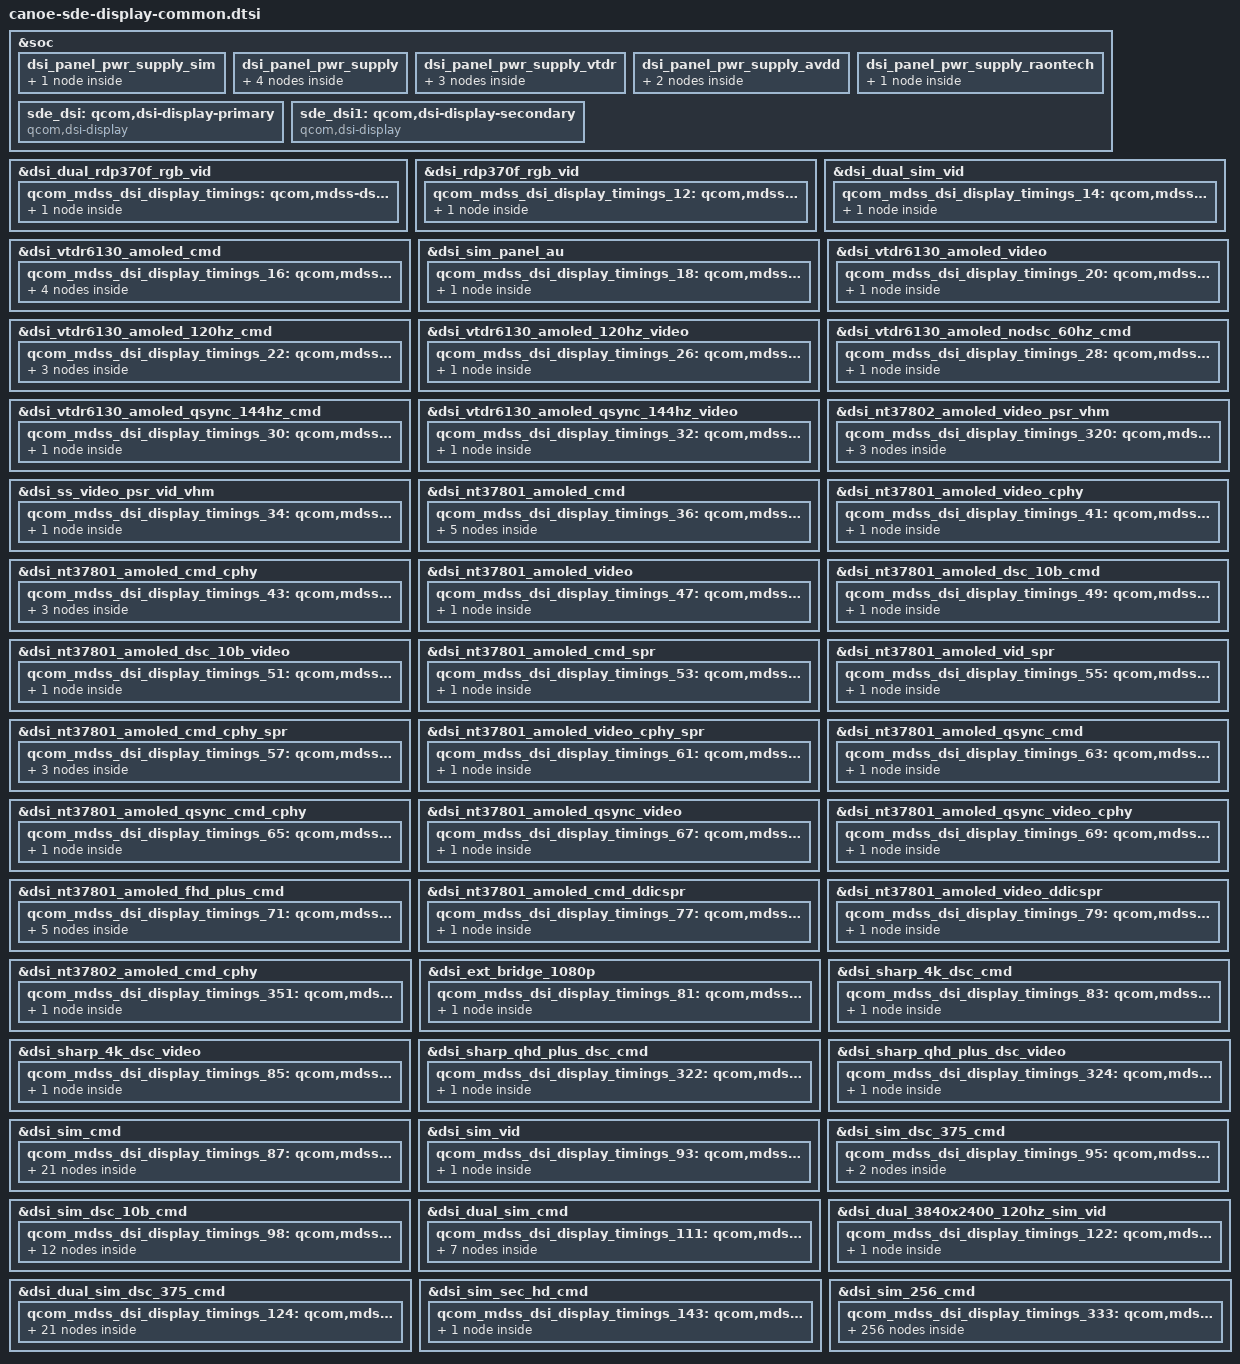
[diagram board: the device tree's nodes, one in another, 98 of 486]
// SPDX-License-Identifier: BSD-3-Clause
/*
 * Copyright (c) Qualcomm Technologies, Inc. and/or its subsidiaries.
 */

#include "dsi-panel-nt37801-dsc-wqhd-plus-cmd.dtsi"
#include "dsi-panel-nt37801-dsc-wqhd-plus-cmd-cphy.dtsi"
#include "dsi-panel-nt37801-dsc-wqhd-plus-video.dtsi"
#include "dsi-panel-nt37801-dsc-wqhd-plus-video-cphy.dtsi"
#include "dsi-panel-nt37801-dsc-10bit-cmd.dtsi"
#include "dsi-panel-nt37801-dsc-10bit-video.dtsi"
#include "dsi-panel-nt37801-dsc-wqhd-plus-cmd-spr.dtsi"
#include "dsi-panel-nt37801-dsc-wqhd-plus-video-spr.dtsi"
#include "dsi-panel-nt37801-qsync-dsc-wqhd-plus-cmd.dtsi"
#include "dsi-panel-nt37801-qsync-dsc-wqhd-plus-cmd-cphy.dtsi"
#include "dsi-panel-nt37801-qsync-dsc-wqhd-plus-video.dtsi"
#include "dsi-panel-nt37801-qsync-dsc-wqhd-plus-video-cphy.dtsi"
#include "dsi-panel-nt37801-dsc-fhd-plus-cmd.dtsi"
#include "dsi-panel-nt37801-dsc-wqhd-plus-cmd-ddicspr.dtsi"
#include "dsi-panel-nt37801-dsc-wqhd-plus-video-ddicspr.dtsi"
#include "dsi-panel-nt37801-dsc-wqhd-plus-cmd-cphy-spr.dtsi"
#include "dsi-panel-nt37801-dsc-wqhd-plus-video-cphy-spr.dtsi"
#include "dsi-panel-nt37802-amoled-video-psr-vhm.dtsi"
#include "dsi-panel-nt37802-dsc-wqhd-plus-cmd-cphy.dtsi"
#include "dsi-panel-sharp-dsc-4k-cmd.dtsi"
#include "dsi-panel-sharp-dsc-4k-video.dtsi"
#include "dsi-panel-sharp-dsc-qhd-plus-cmd.dtsi"
#include "dsi-panel-sharp-dsc-qhd-plus-video.dtsi"
#include "dsi-panel-sim-cmd-au.dtsi"
#include "dsi-panel-sim-cmd.dtsi"
#include "dsi-panel-sim-256-cmd.dtsi"
#include "dsi-panel-sim-dsc-10bit-cmd.dtsi"
#include "dsi-panel-sim-dsc375-cmd.dtsi"
#include "dsi-panel-sim-dualmipi-cmd.dtsi"
#include "dsi-panel-sim-dualmipi-dsc375-cmd.dtsi"
#include "dsi-panel-sim-dualmipi-video.dtsi"
#include "dsi-panel-sim-dualmipi-3840x2400-120hz-video.dtsi"
#include "dsi-panel-sim-sec-hd-cmd.dtsi"
#include "dsi-panel-sim-video.dtsi"
#include "dsi-panel-ss-video-psr-vid-vhm.dtsi"
#include "dsi-panel-vtdr6130-dsc-fhd-plus-120hz-cmd.dtsi"
#include "dsi-panel-vtdr6130-dsc-fhd-plus-120hz-video.dtsi"
#include "dsi-panel-vtdr6130-nodsc-fhd-plus-60hz-cmd.dtsi"
#include "dsi-panel-vtdr6130-dsc-fhd-plus-cmd.dtsi"
#include "dsi-panel-vtdr6130-dsc-fhd-plus-video.dtsi"
#include "dsi-panel-vtdr6130-qsync-dsc-fhd-plus-144hz-cmd.dtsi"
#include "dsi-panel-vtdr6130-qsync-dsc-fhd-plus-144hz-video.dtsi"
#include "dsi-panel-dual-rdp370f-rgb-video.dtsi"
#include "dsi-panel-rdp370f-rgb-video.dtsi"
#include "dsi-panel-ext-bridge-1080p.dtsi"

#include "canoe-sde-display-pinctrl-common.dtsi"

&soc {
	dsi_panel_pwr_supply_sim: dsi_panel_pwr_supply_sim {
		#address-cells = <1>;
		#size-cells = <0>;

		qcom_panel_supply_entry_0: qcom,panel-supply-entry@0 {
			reg = <0>;
			qcom,supply-name = "dummy";
			qcom,supply-min-voltage = <1800000>;
			qcom,supply-max-voltage = <1800000>;
			qcom,supply-enable-load = <220000>;
			qcom,supply-disable-load = <8000>;
			qcom,supply-post-on-sleep = <20>;
		};
	};

	dsi_panel_pwr_supply: dsi_panel_pwr_supply {
		#address-cells = <1>;
		#size-cells = <0>;

		qcom_panel_supply_entry_0_5: qcom,panel-supply-entry@0 {
			reg = <0>;
			qcom,supply-name = "vddio";
			qcom,supply-min-voltage = <1800000>;
			qcom,supply-max-voltage = <1800000>;
			qcom,supply-enable-load = <154000>;
			qcom,supply-disable-load = <277>;
			qcom,supply-post-on-sleep = <20>;
		};

		qcom_panel_supply_entry_1: qcom,panel-supply-entry@1 {
			reg = <1>;
			qcom,supply-name = "vdd";
			qcom,supply-min-voltage = <1045000>;
			qcom,supply-max-voltage = <1100000>;
			qcom,supply-enable-load = <220000>;
			qcom,supply-disable-load = <3>;
			qcom,supply-post-on-sleep = <0>;
		};

		qcom_panel_supply_entry_2: qcom,panel-supply-entry@2 {
			reg = <2>;
			qcom,supply-name = "vci";
			qcom,supply-min-voltage = <3000000>;
			qcom,supply-max-voltage = <3000000>;
			qcom,supply-enable-load = <10000>;
			qcom,supply-disable-load = <1>;
			qcom,supply-post-on-sleep = <0>;
		};

		qcom_panel_supply_entry_3: qcom,panel-supply-entry@3 {
			reg = <3>;
			qcom,supply-name = "tvdd";
			qcom,supply-min-voltage = <1800000>;
			qcom,supply-max-voltage = <1800000>;
			qcom,supply-enable-load = <0>;
			qcom,supply-disable-load = <0>;
			qcom,supply-post-on-sleep = <20>;
		};
	};

	dsi_panel_pwr_supply_vtdr: dsi_panel_pwr_supply_vtdr {
		#address-cells = <1>;
		#size-cells = <0>;

		qcom_panel_supply_entry_0_6: qcom,panel-supply-entry@0 {
			reg = <0>;
			qcom,supply-name = "vddio";
			qcom,supply-min-voltage = <1800000>;
			qcom,supply-max-voltage = <1800000>;
			qcom,supply-enable-load = <220000>;
			qcom,supply-disable-load = <8000>;
			qcom,supply-post-on-sleep = <20>;
		};

		qcom_panel_supply_entry_1_7: qcom,panel-supply-entry@1 {
			reg = <1>;
			qcom,supply-name = "vci";
			qcom,supply-min-voltage = <3000000>;
			qcom,supply-max-voltage = <3000000>;
			qcom,supply-enable-load = <10000>;
			qcom,supply-disable-load = <300>;
			qcom,supply-post-on-sleep = <1>;
			qcom,supply-post-off-sleep = <2>;
		};

		qcom_panel_supply_entry_2_8: qcom,panel-supply-entry@2 {
			reg = <2>;
			qcom,supply-name = "vdd";
			qcom,supply-min-voltage = <1200000>;
			qcom,supply-max-voltage = <1292000>;
			qcom,supply-enable-load = <200000>;
			qcom,supply-disable-load = <0>;
			qcom,supply-post-on-sleep = <0>;
			qcom,supply-post-off-sleep = <2>;
		};
	};

	dsi_panel_pwr_supply_avdd: dsi_panel_pwr_supply_avdd {
		#address-cells = <1>;
		#size-cells = <0>;

		qcom_panel_supply_entry_0_9: qcom,panel-supply-entry@0 {
			reg = <0>;
			qcom,supply-name = "vddio";
			qcom,supply-min-voltage = <1800000>;
			qcom,supply-max-voltage = <1800000>;
			qcom,supply-enable-load = <220000>;
			qcom,supply-disable-load = <8000>;
			qcom,supply-post-on-sleep = <20>;
		};

		qcom_panel_supply_entry_1_10: qcom,panel-supply-entry@1 {
			reg = <1>;
			qcom,supply-name = "avdd";
			qcom,supply-min-voltage = <4600000>;
			qcom,supply-max-voltage = <7500000>;
			qcom,supply-enable-load = <33000>;
			qcom,supply-disable-load = <1>;
		};
	};

	dsi_panel_pwr_supply_raontech: dsi_panel_pwr_supply_raontech {
		#address-cells = <1>;
		#size-cells = <0>;

		qcom_panel_supply_entry_0_11: qcom,panel-supply-entry@0 {
			reg = <0>;
			qcom,supply-name = "avdd";
			qcom,supply-min-voltage = <4600000>;
			qcom,supply-max-voltage = <7500000>;
			qcom,supply-enable-load = <33000>;
			qcom,supply-disable-load = <1>;
		};
	};

	sde_dsi: qcom,dsi-display-primary {
		compatible = "qcom,dsi-display";
		label = "primary";
		qcom,op-label = "hwio";
		status = "ok";

		qcom,dsi-ctrl = <&mdss_dsi0 &mdss_dsi1>;
		qcom,dsi-phy = <&mdss_dsi_phy0 &mdss_dsi_phy1>;

		qcom,platform-te-gpio = <&tlmm 86 0>;
		qcom,panel-te-source = <0>;

		qcom,mdp = <&mdss_mdp>;
		qcom,dsi-default-panel = <&dsi_nt37801_amoled_cmd>;
		qcom,demura-panel-id = <0x0122e700 0x00000471>;
	};

	sde_dsi1: qcom,dsi-display-secondary {
		compatible = "qcom,dsi-display";
		label = "secondary";
		qcom,op-label = "hwio";
		status = "ok";

		qcom,dsi-ctrl = <&mdss_dsi0 &mdss_dsi1>;
		qcom,dsi-phy = <&mdss_dsi_phy0 &mdss_dsi_phy1>;

		qcom,platform-te-gpio = <&tlmm 87 0>;
		qcom,panel-te-source = <1>;

		qcom,mdp = <&mdss_mdp>;
		qcom,demura-panel-id = <0x0 0x0>;
	};
};

&dsi_dual_rdp370f_rgb_vid {
	qcom,dsi-select-clocks = "pll_byte_clk0", "pll_dsi_clk0";

	qcom,mdss-dsi-panel-status-check-mode = "esd_sw_sim_success";
	qcom,esd-check-enabled;

	qcom_mdss_dsi_display_timings: qcom,mdss-dsi-display-timings {
		timing_0: timing@0 {
			qcom,mdss-dsi-panel-phy-timings = [00 2d 0c 0c 1d 1c 0c
				0c 0b 02 04 00 25 11];
			qcom,display-topology = <2 0 2>;
			qcom,default-topology-index = <0>;
		};
	};
};

&dsi_rdp370f_rgb_vid {
	qcom,dsi-select-clocks = "pll_byte_clk0", "pll_dsi_clk0";

	qcom,mdss-dsi-panel-status-check-mode = "esd_sw_sim_success";
	qcom,esd-check-enabled;

	qcom_mdss_dsi_display_timings_12: qcom,mdss-dsi-display-timings {
		timing_0_13: timing@0 {
			qcom,mdss-dsi-panel-phy-timings = [00 2d 0c 0c 1d 1c 0c
				0c 0b 02 04 00 25 11];
			qcom,display-topology = <1 0 1>;
			qcom,default-topology-index = <0>;
		};
	};
};

&dsi_dual_sim_vid {
	qcom,dsi-select-clocks = "pll_byte_clk0", "pll_dsi_clk0";

	qcom_mdss_dsi_display_timings_14: qcom,mdss-dsi-display-timings {
		timing_0_15: timing@0 {
			qcom,mdss-dsi-panel-phy-timings = [00 1a 07 06 16 21 07
				07 07 02 04 00 17 0c];
			qcom,display-topology = <2 0 2>;
			qcom,default-topology-index = <0>;
		};
	};
};

/* PHY TIMINGS REVISION YL with reduced margins */
&dsi_vtdr6130_amoled_cmd {
	qcom,dsi-select-clocks = "pll_byte_clk0", "pll_dsi_clk0";
	qcom,dsi-select-sec-clocks = "pll_byte_clk1", "pll_dsi_clk1";

	qcom,dsi-dyn-clk-enable;

	qcom,esd-check-enabled;
	qcom,mdss-dsi-panel-status-check-mode = "reg_read";
	qcom,mdss-dsi-panel-status-command = [06 01 00 01 00 00 01 0a];
	qcom,mdss-dsi-panel-status-command-state = "dsi_lp_mode";
	qcom,mdss-dsi-panel-status-value = <0x9c>;
	qcom,mdss-dsi-panel-status-read-length = <1>;

	qcom,mdss-dsi-panel-hdr-enabled;

	qcom_mdss_dsi_display_timings_16: qcom,mdss-dsi-display-timings {
		timing_0_17: timing@0 {
			qcom,mdss-dsi-panel-phy-timings = [00 1c 08 07 17 22 07
				07 08 02 04 00 19 0c];
			qcom,display-topology = <2 2 1>;
			qcom,default-topology-index = <0>;
			qcom,dsi-dyn-clk-list = <813936000 818175250 822414500>;
		};

		timing_1: timing@1 {
			qcom,mdss-dsi-panel-phy-timings = [00 1c 08 07 17 22 07
				07 08 02 04 00 19 0c];
			qcom,display-topology = <2 2 1>;
			qcom,default-topology-index = <0>;
			qcom,dsi-dyn-clk-list = <813936000 818175250 822414500>;
		};

		timing_2: timing@2 {
			qcom,mdss-dsi-panel-phy-timings = [00 1c 08 07 17 22 07
				07 08 02 04 00 19 0c];
			qcom,display-topology = <2 2 1>;
			qcom,default-topology-index = <0>;
			qcom,dsi-dyn-clk-list = <813936000 818175250 822414500>;
		};

		timing_3: timing@3 {
			qcom,mdss-dsi-panel-phy-timings = [00 1c 08 07 17 22 07
				07 08 02 04 00 19 0c];
			qcom,display-topology = <2 2 1>;
			qcom,default-topology-index = <0>;
			qcom,dsi-dyn-clk-list = <813936000 818175250 822414500>;
		};
	};
};

&dsi_sim_panel_au {
	qcom,dsi-select-clocks = "pll_byte_clk0", "pll_dsi_clk0";
	qcom_mdss_dsi_display_timings_18: qcom,mdss-dsi-display-timings {
		timing_0_19: timing@0 {
			qcom,mdss-dsi-panel-phy-timings = [00 1c 08 07 17 22 07
				07 08 02 04 00 19 0c];
			qcom,display-topology = <2 2 1>;
			qcom,default-topology-index = <0>;
		};
	};
};

&dsi_vtdr6130_amoled_video {
	qcom,dsi-select-clocks = "pll_byte_clk0", "pll_dsi_clk0";
	qcom,dsi-select-sec-clocks = "pll_byte_clk1", "pll_dsi_clk1";
	qcom,dsi-supported-dfps-list = <144 120 90 60>;
	qcom,mdss-dsi-pan-enable-dynamic-fps;
	qcom,mdss-dsi-pan-fps-update = "dfps_immediate_porch_mode_vfp";

	qcom,dsi-dyn-clk-enable;
	qcom,dsi-dyn-clk-type = "constant-fps-adjust-hfp";

	qcom,esd-check-enabled;
	qcom,mdss-dsi-panel-status-check-mode = "reg_read";
	qcom,mdss-dsi-panel-status-command = [06 01 00 01 00 00 01 0a];
	qcom,mdss-dsi-panel-status-command-state = "dsi_lp_mode";
	qcom,mdss-dsi-panel-status-value = <0x9c>;
	qcom,mdss-dsi-panel-status-read-length = <1>;

	qcom,mdss-dsi-panel-hdr-enabled;

	qcom_mdss_dsi_display_timings_20: qcom,mdss-dsi-display-timings {
		timing_0_21: timing@0 {
			qcom,mdss-dsi-panel-phy-timings = [00 1c 08 07 17 22 07
				07 08 02 04 00 19 0c];
			qcom,display-topology = <2 2 1>;
			qcom,default-topology-index = <0>;
			qcom,dsi-dyn-clk-list = <847480320 844537680 841595040>;
		};
	};
};

&dsi_vtdr6130_amoled_120hz_cmd {
	qcom,dsi-select-clocks = "pll_byte_clk0", "pll_dsi_clk0";

	qcom,esd-check-enabled;
	qcom,mdss-dsi-panel-status-check-mode = "reg_read";
	qcom,mdss-dsi-panel-status-command = [06 01 00 01 00 00 01 0a];
	qcom,mdss-dsi-panel-status-command-state = "dsi_lp_mode";
	qcom,mdss-dsi-panel-status-value = <0x9c>;
	qcom,mdss-dsi-panel-status-read-length = <1>;

	qcom,mdss-dsi-panel-hdr-enabled;

	qcom_mdss_dsi_display_timings_22: qcom,mdss-dsi-display-timings {
		timing_0_23: timing@0 {
			qcom,mdss-dsi-panel-phy-timings = [00 19 06 06 15 20 07
				06 07 02 04 00 16 0b];
			qcom,display-topology = <2 2 1>;
			qcom,default-topology-index = <0>;
		};

		timing_1_24: timing@1 {
			qcom,mdss-dsi-panel-phy-timings = [00 19 06 06 15 20 07
				06 07 02 04 00 16 0b];
			qcom,display-topology = <2 2 1>;
			qcom,default-topology-index = <0>;
		};

		timing_2_25: timing@2 {
			qcom,mdss-dsi-panel-phy-timings = [00 19 06 06 15 20 07
				06 07 02 04 00 16 0b];
			qcom,display-topology = <2 2 1>;
			qcom,default-topology-index = <0>;
		};
	};
};

&dsi_vtdr6130_amoled_120hz_video {
	qcom,dsi-select-clocks = "pll_byte_clk0", "pll_dsi_clk0";
	qcom,dsi-supported-dfps-list = <120 90 60>;
	qcom,mdss-dsi-pan-enable-dynamic-fps;
	qcom,mdss-dsi-pan-fps-update = "dfps_immediate_porch_mode_vfp";

	qcom,esd-check-enabled;
	qcom,mdss-dsi-panel-status-check-mode = "reg_read";
	qcom,mdss-dsi-panel-status-command = [06 01 00 01 00 00 01 0a];
	qcom,mdss-dsi-panel-status-command-state = "dsi_lp_mode";
	qcom,mdss-dsi-panel-status-value = <0x9c>;
	qcom,mdss-dsi-panel-status-read-length = <1>;

	qcom,mdss-dsi-panel-hdr-enabled;

	qcom_mdss_dsi_display_timings_26: qcom,mdss-dsi-display-timings {
		timing_0_27: timing@0 {
			qcom,mdss-dsi-panel-phy-timings = [00 19 06 06 15 20 07
				06 07 02 04 00 16 0b];
			qcom,display-topology = <2 2 1>;
			qcom,default-topology-index = <0>;
		};
	};
};

&dsi_vtdr6130_amoled_nodsc_60hz_cmd {
	qcom,dsi-select-clocks = "pll_byte_clk0", "pll_dsi_clk0";

	qcom_mdss_dsi_display_timings_28: qcom,mdss-dsi-display-timings {
		timing_0_29: timing@0 {
			qcom,mdss-dsi-panel-phy-timings = [00 21 08 08 19 23 09
				08 09 02 04 00 1c 0d];
			qcom,display-topology = <1 0 1>;
			qcom,default-topology-index = <0>;
		};
	};
};

&dsi_vtdr6130_amoled_qsync_144hz_cmd {
	qcom,dsi-select-clocks = "pll_byte_clk0", "pll_dsi_clk0";
	qcom,esd-check-enabled;
	qcom,mdss-dsi-panel-status-check-mode = "reg_read";
	qcom,mdss-dsi-panel-status-command = [06 01 00 01 00 00 01 0a];
	qcom,mdss-dsi-panel-status-command-state = "dsi_lp_mode";
	qcom,mdss-dsi-panel-status-value = <0x9c>;
	qcom,mdss-dsi-panel-status-read-length = <1>;

	qcom,mdss-dsi-panel-hdr-enabled;

	qcom_mdss_dsi_display_timings_30: qcom,mdss-dsi-display-timings {
		timing_0_31: timing@0 {
			qcom,mdss-dsi-panel-phy-timings = [00 1c 08 07 17 22 07
				07 08 02 04 00 19 0c];
			qcom,display-topology = <2 2 1>;
			qcom,default-topology-index = <0>;
		};
	};
};

&dsi_vtdr6130_amoled_qsync_144hz_video {
	qcom,dsi-select-clocks = "pll_byte_clk0", "pll_dsi_clk0";
	qcom,esd-check-enabled;
	qcom,mdss-dsi-panel-status-check-mode = "reg_read";
	qcom,mdss-dsi-panel-status-command = [06 01 00 01 00 00 01 0a];
	qcom,mdss-dsi-panel-status-command-state = "dsi_lp_mode";
	qcom,mdss-dsi-panel-status-value = <0x9c>;
	qcom,mdss-dsi-panel-status-read-length = <1>;

	qcom,mdss-dsi-panel-hdr-enabled;

	qcom_mdss_dsi_display_timings_32: qcom,mdss-dsi-display-timings {
		timing_0_33: timing@0 {
			qcom,mdss-dsi-panel-phy-timings = [00 1c 08 07 17 22 07
				07 08 02 04 00 19 0c];
			qcom,display-topology = <2 2 1>;
			qcom,default-topology-index = <0>;
		};
	};
};

&dsi_nt37802_amoled_video_psr_vhm {
	qcom,dsi-select-clocks = "pll_byte_clk0", "pll_dsi_clk0";

	qcom,esd-check-enabled;
	qcom,mdss-dsi-panel-status-check-mode = "reg_read";
	qcom,mdss-dsi-panel-status-command = [06 01 00 01 00 00 01 0a];
	qcom,mdss-dsi-panel-status-command-state = "dsi_lp_mode";
	qcom,mdss-dsi-panel-status-value = <0x9c>;
	qcom,mdss-dsi-panel-status-read-length = <1>;

	qcom_mdss_dsi_display_timings_320: qcom,mdss-dsi-display-timings {
		timing_0_321: timing@0 {
			qcom,mdss-esync-hsync-milli-pulse-width = <500>;
			qcom,mdss-esync-emsync-fps = <120>;
			qcom,mdss-esync-emsync-milli-pulse-width = <500>;
			qcom,dsi-qsync-mode-avr-step-fps = <120>;
			qcom,mdss-dsi-panel-phy-timings = [00 24 0A 0A 1A 18 0A
					0A 09 02 04 00 1E 0F];
			qcom,display-topology = <2 2 1>;
			qcom,default-topology-index = <0>;
		};

		timing_1_322: timing@1 {
			qcom,mdss-esync-hsync-milli-pulse-width = <500>;
			qcom,mdss-esync-emsync-fps = <360>;
			qcom,mdss-esync-emsync-milli-pulse-width = <500>;
			qcom,dsi-qsync-mode-avr-step-fps = <360>;
			qcom,mdss-dsi-panel-phy-timings = [00 24 0A 0A 1A 18 0A
					0A 09 02 04 00 1E 0F];
			qcom,display-topology = <2 2 1>;
			qcom,default-topology-index = <0>;
		};

		timing_2_323: timing@2 {
			qcom,mdss-esync-hsync-milli-pulse-width = <500>;
			qcom,mdss-esync-emsync-fps = <90>;
			qcom,mdss-esync-emsync-milli-pulse-width = <500>;
			qcom,dsi-qsync-mode-avr-step-fps = <90>;
			qcom,mdss-dsi-panel-phy-timings = [00 24 0A 0A 1A 18 0A
					0A 09 02 04 00 1E 0F];
			qcom,display-topology = <2 2 1>;
			qcom,default-topology-index = <0>;
		};
	};
};

&dsi_ss_video_psr_vid_vhm {
	qcom,dsi-select-clocks = "pll_byte_clk0", "pll_dsi_clk0";
	qcom,dsi-select-sec-clocks = "pll_byte_clk1", "pll_dsi_clk1";
	qcom,dsi-dyn-clk-enable;

	qcom_mdss_dsi_display_timings_34: qcom,mdss-dsi-display-timings {
		timing_0_35: timing@0 {
			qcom,mdss-dsi-panel-phy-timings = [00 2D 0C 0C 1D 27 0C
					0D 0B 02 04 00 25 11];
			qcom,display-topology = <2 2 1>;
			qcom,default-topology-index = <0>;
			qcom,dsi-dyn-clk-list = <1406283648 1412167680 1418051712>;
		};
	};
};

&dsi_nt37801_amoled_cmd {
	qcom,dsi-select-clocks = "pll_byte_clk0", "pll_dsi_clk0";
	qcom,dsi-select-sec-clocks = "pll_byte_clk1", "pll_dsi_clk1";
	qcom,esd-check-enabled;
	qcom,mdss-dsi-panel-status-check-mode = "reg_read";
	qcom,mdss-dsi-panel-status-command = [06 01 00 01 00 00 01 0a];
	qcom,mdss-dsi-panel-status-command-state = "dsi_lp_mode";
	qcom,mdss-dsi-panel-status-value = <0x9c>;
	qcom,mdss-dsi-panel-status-read-length = <1>;

	qcom_mdss_dsi_display_timings_36: qcom,mdss-dsi-display-timings {
		timing_0_37: timing@0 {
			qcom,mdss-dsi-panel-phy-timings = [00 28 0a 0b 1b 1a 0a
					0b 0a 02 04 00 21 0f];
			qcom,display-topology = <2 2 1>;
			qcom,default-topology-index = <0>;
		};

		timing_1_38: timing@1 {
			qcom,mdss-dsi-panel-phy-timings = [00 1f 08 07 18 22 08
					08 08 08 02 04 1a 0d];
			qcom,display-topology = <2 2 1>;
			qcom,default-topology-index = <0>;
		};

		timing_2_39: timing@2 {
			qcom,mdss-dsi-panel-phy-timings = [00 28 0a 0b 1b 1a 0a
					0b 0a 02 04 00 21 0f];
			qcom,display-topology = <2 2 1>;
			qcom,default-topology-index = <0>;
		};

		timing_3_40: timing@3 {
			qcom,mdss-dsi-panel-phy-timings = [00 28 0a 0b 1b 1a 0a
					0b 0a 02 04 00 21 0f];
			qcom,display-topology = <2 2 1>;
			qcom,default-topology-index = <0>;
		};

		timing_4: timing@4 {
			qcom,mdss-dsi-panel-phy-timings = [00 28 0a 0b 1b 1a 0a
					0b 0a 02 04 00 21 0f];
			qcom,display-topology = <2 2 1>;
			qcom,default-topology-index = <0>;
		};
	};
};

&dsi_nt37801_amoled_video_cphy {
	qcom,dsi-select-clocks = "pll_byte_clk0", "pll_dsi_clk0";
	qcom,dsi-supported-dfps-list = <120 110 100 90 80>;
	qcom,mdss-dsi-pan-enable-dynamic-fps;
	qcom,mdss-dsi-pan-fps-update = "dfps_immediate_porch_mode_vfp";

	qcom,esd-check-enabled;
	qcom,mdss-dsi-panel-status-check-mode = "reg_read";
	qcom,mdss-dsi-panel-status-command = [06 01 00 01 00 00 01 0a];
	qcom,mdss-dsi-panel-status-command-state = "dsi_lp_mode";
	qcom,mdss-dsi-panel-status-value = <0x9c>;
	qcom,mdss-dsi-panel-status-read-length = <1>;

	qcom_mdss_dsi_display_timings_41: qcom,mdss-dsi-display-timings {
		timing_0_42: timing@0 {
			qcom,mdss-dsi-panel-phy-timings = [00 00 00 00 25 25 08
				19 09 02 04 00 00 00];
			qcom,display-topology = <2 2 1>;
			qcom,default-topology-index = <0>;
		};
	};
};

&dsi_nt37801_amoled_cmd_cphy {
	qcom,dsi-select-clocks = "pll_byte_clk0", "pll_dsi_clk0";
	qcom,esd-check-enabled;
	qcom,mdss-dsi-panel-status-check-mode = "reg_read";
	qcom,mdss-dsi-panel-status-command = [06 01 00 01 00 00 01 0a];
	qcom,mdss-dsi-panel-status-command-state = "dsi_lp_mode";
	qcom,mdss-dsi-panel-status-value = <0x9c>;
	qcom,mdss-dsi-panel-status-read-length = <1>;

	qcom_mdss_dsi_display_timings_43: qcom,mdss-dsi-display-timings {
		timing_0_44: timing@0 {
			qcom,mdss-dsi-panel-phy-timings = [00 00 00 00 23 22 08
				19 08 02 04 00 00 00];
			qcom,display-topology = <2 2 1>;
			qcom,default-topology-index = <0>;
		};

		timing_1_45: timing@1 {
			qcom,mdss-dsi-panel-phy-timings = [00 00 00 00 20 1c 06
				19 06 02 04 00 00 00];
			qcom,display-topology = <2 2 1>;
			qcom,default-topology-index = <0>;
		};

		timing_2_46: timing@2 {
			qcom,mdss-dsi-panel-phy-timings = [00 00 00 00 23 22 08
				19 08 02 04 00 00 00];
			qcom,display-topology = <2 2 1>;
			qcom,default-topology-index = <0>;
		};
	};
};

&dsi_nt37801_amoled_video {
	qcom,dsi-select-clocks = "pll_byte_clk0", "pll_dsi_clk0";
	qcom,dsi-select-sec-clocks = "pll_byte_clk1", "pll_dsi_clk1";
	qcom,dsi-supported-dfps-list = <120 110 100 90 80>;
	qcom,mdss-dsi-pan-enable-dynamic-fps;
	qcom,mdss-dsi-pan-fps-update = "dfps_immediate_porch_mode_vfp";

	qcom,esd-check-enabled;
	qcom,mdss-dsi-panel-status-check-mode = "reg_read";
	qcom,mdss-dsi-panel-status-command = [06 01 00 01 00 00 01 0a];
	qcom,mdss-dsi-panel-status-command-state = "dsi_lp_mode";
	qcom,mdss-dsi-panel-status-value = <0x9c>;
	qcom,mdss-dsi-panel-status-read-length = <1>;

	qcom_mdss_dsi_display_timings_47: qcom,mdss-dsi-display-timings {
		timing_0_48: timing@0 {
			qcom,mdss-dsi-panel-phy-timings = [00 28 0a 0b 1b 1a 0a
					0b 0a 02 04 00 21 0f];
			qcom,display-topology = <2 2 1>;
			qcom,default-topology-index = <0>;
		};
	};
};

&dsi_nt37801_amoled_dsc_10b_cmd {
	qcom,dsi-select-clocks = "pll_byte_clk0", "pll_dsi_clk0";
	qcom,dsi-select-sec-clocks = "pll_byte_clk1", "pll_dsi_clk1";
	qcom,esd-check-enabled;
	qcom,mdss-dsi-panel-status-check-mode = "reg_read";
	qcom,mdss-dsi-panel-status-command = [06 01 00 01 00 00 01 0a];
	qcom,mdss-dsi-panel-status-command-state = "dsi_lp_mode";
	qcom,mdss-dsi-panel-status-value = <0x9c>;
	qcom,mdss-dsi-panel-status-read-length = <1>;

	qcom_mdss_dsi_display_timings_49: qcom,mdss-dsi-display-timings {
		timing_0_50: timing@0 {
			qcom,mdss-dsi-panel-phy-timings = [00 35 0d 0d 1f 1c 0d
					0e 0e 0c 02 04 2a 12];
			qcom,display-topology = <2 2 1>;
			qcom,default-topology-index = <0>;
		};
	};
};

&dsi_nt37801_amoled_dsc_10b_video {
	qcom,dsi-select-clocks = "pll_byte_clk0", "pll_dsi_clk0";
	qcom,dsi-supported-dfps-list = <120 110 100 90 80>;
	qcom,mdss-dsi-pan-enable-dynamic-fps;
	qcom,mdss-dsi-pan-fps-update = "dfps_immediate_porch_mode_vfp";

	qcom,esd-check-enabled;
	qcom,mdss-dsi-panel-status-check-mode = "reg_read";
	qcom,mdss-dsi-panel-status-command = [06 01 00 01 00 00 01 0a];
	qcom,mdss-dsi-panel-status-command-state = "dsi_lp_mode";
	qcom,mdss-dsi-panel-status-value = <0x9c>;
	qcom,mdss-dsi-panel-status-read-length = <1>;

	qcom_mdss_dsi_display_timings_51: qcom,mdss-dsi-display-timings {
		timing_0_52: timing@0 {
			qcom,mdss-dsi-panel-phy-timings = [00 3e 0f 0f 22 1f 0f
					10 0e 02 04 00 30 14];
			qcom,display-topology = <2 2 1>;
			qcom,default-topology-index = <0>;
		};
	};
};

&dsi_nt37801_amoled_cmd_spr {
	qcom,dsi-select-clocks = "pll_byte_clk0", "pll_dsi_clk0";
	qcom,dsi-select-sec-clocks = "pll_byte_clk1", "pll_dsi_clk1";
	qcom,esd-check-enabled;
	qcom,mdss-dsi-panel-status-check-mode = "reg_read";
	qcom,mdss-dsi-panel-status-command = [06 01 00 01 00 00 01 0a];
	qcom,mdss-dsi-panel-status-command-state = "dsi_lp_mode";
	qcom,mdss-dsi-panel-status-value = <0x9c>;
	qcom,mdss-dsi-panel-status-read-length = <1>;

	qcom_mdss_dsi_display_timings_53: qcom,mdss-dsi-display-timings {
		timing_0_54: timing@0 {
			qcom,mdss-dsi-panel-phy-timings = [00 28 0a 0b 1b 1a 0a
					0b 0a 02 04 00 21 0f];
			qcom,display-topology = <2 2 1>;
			qcom,default-topology-index = <0>;
		};
	};
};

&dsi_nt37801_amoled_vid_spr {
	qcom,dsi-select-clocks = "pll_byte_clk0", "pll_dsi_clk0";
	qcom,dsi-select-sec-clocks = "pll_byte_clk1", "pll_dsi_clk1";
	qcom,esd-check-enabled;
	qcom,mdss-dsi-panel-status-check-mode = "reg_read";
	qcom,mdss-dsi-panel-status-command = [06 01 00 01 00 00 01 0a];
	qcom,mdss-dsi-panel-status-command-state = "dsi_lp_mode";
	qcom,mdss-dsi-panel-status-value = <0x9c>;
	qcom,mdss-dsi-panel-status-read-length = <1>;

	qcom_mdss_dsi_display_timings_55: qcom,mdss-dsi-display-timings {
		timing_0_56: timing@0 {
			qcom,mdss-dsi-panel-phy-timings = [00 28 0a 0b 1b 1a 0a
					0b 0a 02 04 00 21 0f];
			qcom,display-topology = <2 2 1>;
			qcom,default-topology-index = <0>;
		};
	};
};

&dsi_nt37801_amoled_cmd_cphy_spr {
	qcom,dsi-select-clocks = "pll_byte_clk0", "pll_dsi_clk0";
	qcom,esd-check-enabled;
	qcom,mdss-dsi-panel-status-check-mode = "reg_read";
	qcom,mdss-dsi-panel-status-command = [06 01 00 01 00 00 01 0a];
	qcom,mdss-dsi-panel-status-command-state = "dsi_lp_mode";
	qcom,mdss-dsi-panel-status-value = <0x9c>;
	qcom,mdss-dsi-panel-status-read-length = <1>;

	qcom_mdss_dsi_display_timings_57: qcom,mdss-dsi-display-timings {
		timing_0_58: timing@0 {
			qcom,mdss-dsi-panel-phy-timings = [00 00 00 00 23 22 08
				19 08 02 04 00 00 00];
			qcom,display-topology = <2 2 1>;
			qcom,default-topology-index = <0>;
		};

		timing_1_59: timing@1 {
			qcom,mdss-dsi-panel-phy-timings = [00 00 00 00 20 1c 06
				19 06 02 04 00 00 00];
			qcom,display-topology = <2 2 1>;
			qcom,default-topology-index = <0>;
		};

		timing_2_60: timing@2 {
			qcom,mdss-dsi-panel-phy-timings = [00 00 00 00 23 22 08
				19 08 02 04 00 00 00];
			qcom,display-topology = <2 2 1>;
			qcom,default-topology-index = <0>;
		};
	};
};

&dsi_nt37801_amoled_video_cphy_spr {
	qcom,dsi-select-clocks = "pll_byte_clk0", "pll_dsi_clk0";
	qcom,dsi-supported-dfps-list = <120 110 100 90 80>;
	qcom,mdss-dsi-pan-enable-dynamic-fps;
	qcom,mdss-dsi-pan-fps-update = "dfps_immediate_porch_mode_vfp";

	qcom,esd-check-enabled;
	qcom,mdss-dsi-panel-status-check-mode = "reg_read";
	qcom,mdss-dsi-panel-status-command = [06 01 00 01 00 00 01 0a];
	qcom,mdss-dsi-panel-status-command-state = "dsi_lp_mode";
	qcom,mdss-dsi-panel-status-value = <0x9c>;
	qcom,mdss-dsi-panel-status-read-length = <1>;

	qcom_mdss_dsi_display_timings_61: qcom,mdss-dsi-display-timings {
		timing_0_62: timing@0 {
			qcom,mdss-dsi-panel-phy-timings = [00 00 00 00 25 25 08
				19 09 02 04 00 00 00];
			qcom,display-topology = <2 2 1>;
			qcom,default-topology-index = <0>;
		};
	};
};

&dsi_nt37801_amoled_qsync_cmd {
	qcom,dsi-select-clocks = "pll_byte_clk0", "pll_dsi_clk0";
	qcom,dsi-select-sec-clocks = "pll_byte_clk1", "pll_dsi_clk1";
	qcom,esd-check-enabled;
	qcom,mdss-dsi-panel-status-check-mode = "reg_read";
	qcom,mdss-dsi-panel-status-command = [06 01 00 01 00 00 01 0a];
	qcom,mdss-dsi-panel-status-command-state = "dsi_lp_mode";
	qcom,mdss-dsi-panel-status-value = <0x9c>;
	qcom,mdss-dsi-panel-status-read-length = <1>;

	qcom_mdss_dsi_display_timings_63: qcom,mdss-dsi-display-timings {
		timing_0_64: timing@0 {
			qcom,mdss-dsi-panel-phy-timings = [00 28 0a 0b 1b 1a 0a
					0b 0a 02 04 00 21 0f];
			qcom,display-topology = <2 2 1>;
			qcom,default-topology-index = <0>;
		};
	};
};

&dsi_nt37801_amoled_qsync_cmd_cphy {
	qcom,dsi-select-clocks = "pll_byte_clk0", "pll_dsi_clk0";
	qcom,esd-check-enabled;
	qcom,mdss-dsi-panel-status-check-mode = "reg_read";
	qcom,mdss-dsi-panel-status-command = [06 01 00 01 00 00 01 0a];
	qcom,mdss-dsi-panel-status-command-state = "dsi_lp_mode";
	qcom,mdss-dsi-panel-status-value = <0x9c>;
	qcom,mdss-dsi-panel-status-read-length = <1>;

	qcom_mdss_dsi_display_timings_65: qcom,mdss-dsi-display-timings {
		timing_0_66: timing@0 {
			qcom,mdss-dsi-panel-phy-timings = [00 00 00 00 23 22 08
				19 08 02 04 00 00 00];
			qcom,display-topology = <2 2 1>;
			qcom,default-topology-index = <0>;
		};
	};
};

&dsi_nt37801_amoled_qsync_video {
	qcom,dsi-select-clocks = "pll_byte_clk0", "pll_dsi_clk0";
	qcom,dsi-select-sec-clocks = "pll_byte_clk1", "pll_dsi_clk1";
	qcom,esd-check-enabled;
	qcom,mdss-dsi-panel-status-check-mode = "reg_read";
	qcom,mdss-dsi-panel-status-command = [06 01 00 01 00 00 01 0a];
	qcom,mdss-dsi-panel-status-command-state = "dsi_lp_mode";
	qcom,mdss-dsi-panel-status-value = <0x9c>;
	qcom,mdss-dsi-panel-status-read-length = <1>;

	qcom_mdss_dsi_display_timings_67: qcom,mdss-dsi-display-timings {
		timing_0_68: timing@0 {
			qcom,mdss-dsi-panel-phy-timings = [00 28 0a 0b 1b 1a 0a
					0b 0a 02 04 00 21 0f];
			qcom,display-topology = <2 2 1>;
			qcom,default-topology-index = <0>;
		};
	};
};

&dsi_nt37801_amoled_qsync_video_cphy {
	qcom,dsi-select-clocks = "pll_byte_clk0", "pll_dsi_clk0";
	qcom,esd-check-enabled;
	qcom,mdss-dsi-panel-status-check-mode = "reg_read";
	qcom,mdss-dsi-panel-status-command = [06 01 00 01 00 00 01 0a];
	qcom,mdss-dsi-panel-status-command-state = "dsi_lp_mode";
	qcom,mdss-dsi-panel-status-value = <0x9c>;
	qcom,mdss-dsi-panel-status-read-length = <1>;

	qcom_mdss_dsi_display_timings_69: qcom,mdss-dsi-display-timings {
		timing_0_70: timing@0 {
			qcom,mdss-dsi-panel-phy-timings = [00 00 00 00 25 25 08
				19 09 02 04 00 00 00];
			qcom,display-topology = <2 2 1>;
			qcom,default-topology-index = <0>;
		};
	};
};

&dsi_nt37801_amoled_fhd_plus_cmd {
	qcom,dsi-select-clocks = "pll_byte_clk0", "pll_dsi_clk0";
	qcom,dsi-select-sec-clocks = "pll_byte_clk1", "pll_dsi_clk1";
	qcom,esd-check-enabled;
	qcom,mdss-dsi-panel-status-check-mode = "reg_read";
	qcom,mdss-dsi-panel-status-command = [06 01 00 01 00 00 01 0a];
	qcom,mdss-dsi-panel-status-command-state = "dsi_lp_mode";
	qcom,mdss-dsi-panel-status-value = <0x9c>;
	qcom,mdss-dsi-panel-status-read-length = <1>;

	qcom_mdss_dsi_display_timings_71: qcom,mdss-dsi-display-timings {
		timing_0_72: timing@0 {
			qcom,mdss-dsi-panel-phy-timings = [00 28 0a 0b 1b 1a 0a
						0b 0a 02 04 00 21 0f];
			qcom,display-topology = <2 2 1>;
			qcom,default-topology-index = <0>;
		};

		timing_1_73: timing@1 {
			qcom,mdss-dsi-panel-phy-timings = [00 19 06 06 15 14 07
					06 06 07 02 04 16 0b];
			qcom,display-topology = <2 2 1>;
			qcom,default-topology-index = <0>;
		};

		timing_2_74: timing@2 {
			qcom,mdss-dsi-panel-phy-timings = [00 19 06 06 15 14 07
					06 06 07 02 04 16 0b];
			qcom,display-topology = <2 2 1>;
			qcom,default-topology-index = <0>;
		};

		timing_3_75: timing@3 {
			qcom,mdss-dsi-panel-phy-timings = [00 19 06 06 15 14 07
					06 06 07 02 04 16 0b];
			qcom,display-topology = <2 2 1>;
			qcom,default-topology-index = <0>;
		};

		timing_4_76: timing@4 {
			qcom,mdss-dsi-panel-phy-timings = [00 19 06 06 15 14 07
					06 06 07 02 04 16 0b];
			qcom,display-topology = <2 2 1>;
			qcom,default-topology-index = <0>;
		};
	};
};

&dsi_nt37801_amoled_cmd_ddicspr {
	qcom,dsi-select-clocks = "pll_byte_clk0", "pll_dsi_clk0";
	qcom,dsi-select-sec-clocks = "pll_byte_clk1", "pll_dsi_clk1";
	qcom,esd-check-enabled;
	qcom,mdss-dsi-panel-status-check-mode = "reg_read";
	qcom,mdss-dsi-panel-status-command = [06 01 00 01 00 00 01 0a];
	qcom,mdss-dsi-panel-status-command-state = "dsi_lp_mode";
	qcom,mdss-dsi-panel-status-value = <0x9c>;
	qcom,mdss-dsi-panel-status-read-length = <1>;

	qcom_mdss_dsi_display_timings_77: qcom,mdss-dsi-display-timings {
		timing_0_78: timing@0 {
			qcom,mdss-dsi-panel-phy-timings = [00 28 0a 0b 1b 1a 0a
					0b 0a 02 04 00 21 0f];
			qcom,display-topology = <2 2 1>;
			qcom,default-topology-index = <0>;
		};
	};
};

&dsi_nt37801_amoled_video_ddicspr {
	qcom,dsi-select-clocks = "pll_byte_clk0", "pll_dsi_clk0";
	qcom,dsi-select-sec-clocks = "pll_byte_clk1", "pll_dsi_clk1";
	qcom,esd-check-enabled;
	qcom,mdss-dsi-panel-status-check-mode = "reg_read";
	qcom,mdss-dsi-panel-status-command = [06 01 00 01 00 00 01 0a];
	qcom,mdss-dsi-panel-status-command-state = "dsi_lp_mode";
	qcom,mdss-dsi-panel-status-value = <0x9c>;
	qcom,mdss-dsi-panel-status-read-length = <1>;

	qcom_mdss_dsi_display_timings_79: qcom,mdss-dsi-display-timings {
		timing_0_80: timing@0 {
			qcom,mdss-dsi-panel-phy-timings = [00 28 0a 0b 1b 1a 0a
					0b 0a 02 04 00 21 0f];
			qcom,display-topology = <2 2 1>;
			qcom,default-topology-index = <0>;
		};
	};
};

&dsi_nt37802_amoled_cmd_cphy {
	qcom,dsi-select-clocks = "pll_byte_clk0", "pll_dsi_clk0";

	qcom_mdss_dsi_display_timings_351: qcom,mdss-dsi-display-timings {
		timing_0_352: timing@0 {
			qcom,mdss-dsi-panel-phy-timings = [00 00 00 00 23 23 08
				19 08 02 04 00 00 00];
			qcom,display-topology = <2 2 1>;
			qcom,default-topology-index = <0>;
		};
	};
};

&dsi_ext_bridge_1080p {
	qcom,dsi-select-clocks = "pll_byte_clk0", "pll_dsi_clk0";
	qcom_mdss_dsi_display_timings_81: qcom,mdss-dsi-display-timings {
		timing_0_82: timing@0 {
			qcom,mdss-dsi-panel-phy-timings = [00 1e 08 07 18 22 08
				08 08 02 04 1a 0c 00];
			qcom,display-topology = <1 0 1>;
		};
	};
};

&dsi_sharp_4k_dsc_cmd {
	qcom,dsi-select-clocks = "pll_byte_clk0", "pll_dsi_clk0";

	qcom,mdss-dsi-panel-status-check-mode = "reg_read";
	qcom,mdss-dsi-panel-status-command = [06 01 00 01 00 00 01 0c];
	qcom,mdss-dsi-panel-status-command-state = "dsi_hs_mode";
	qcom,mdss-dsi-panel-status-value = <0x77>;
	qcom,mdss-dsi-panel-on-check-value = <0x77>;
	qcom,mdss-dsi-panel-status-read-length = <1>;
	qcom,esd-check-enabled;

	qcom_mdss_dsi_display_timings_83: qcom,mdss-dsi-display-timings {
		timing_0_84: timing@0 {
			qcom,mdss-dsi-panel-phy-timings = [00 13 05 04 13 1e 05
				05 06 02 04 00 12 0a];
			qcom,display-topology = <2 2 2>,
						<4 3 2>;
			qcom,default-topology-index = <0>;
		};
	};
};

&dsi_sharp_4k_dsc_video {
	qcom,dsi-select-clocks = "pll_byte_clk0", "pll_dsi_clk0";

	qcom,mdss-dsi-panel-status-check-mode = "reg_read";
	qcom,mdss-dsi-panel-status-command = [06 01 00 01 00 00 01 0c];
	qcom,mdss-dsi-panel-status-command-state = "dsi_lp_mode";
	qcom,mdss-dsi-panel-status-value = <0x77>;
	qcom,mdss-dsi-panel-on-check-value = <0x77>;
	qcom,mdss-dsi-panel-status-read-length = <1>;
	qcom,esd-check-enabled;

	qcom_mdss_dsi_display_timings_85: qcom,mdss-dsi-display-timings {
		timing_0_86: timing@0 {
			qcom,mdss-dsi-panel-phy-timings = [00 18 06 06 15 20 06
				06 07 02 04 00 15 0b];
			qcom,display-topology = <2 2 2>,
						<4 3 2>;
			qcom,default-topology-index = <0>;
		};
	};
};

&dsi_sharp_qhd_plus_dsc_cmd {
	qcom,dsi-select-clocks = "pll_byte_clk0", "pll_dsi_clk0";

	qcom,esd-check-enabled;
	qcom,mdss-dsi-panel-status-check-mode = "reg_read";
	qcom,mdss-dsi-panel-status-command = [06 01 00 01 00 00 01 0c];
	qcom,mdss-dsi-panel-status-command-state = "dsi_lp_mode";
	qcom,mdss-dsi-panel-status-value = <0x07>;
	qcom,mdss-dsi-panel-status-read-length = <1>;

	qcom_mdss_dsi_display_timings_322: qcom,mdss-dsi-display-timings {
		timing_0_323: timing@0 { /* 120 FPS */
			qcom,mdss-dsi-panel-phy-timings = [00 1a 07 06 16 15 07
				07 07 02 04 00 17 0c];
			qcom,display-topology = <4 4 2>;
			qcom,default-topology-index = <0>;
		};
	};
};

&dsi_sharp_qhd_plus_dsc_video {
	qcom,dsi-select-clocks = "pll_byte_clk0", "pll_dsi_clk0";

	qcom,esd-check-enabled;
	qcom,mdss-dsi-panel-status-check-mode = "reg_read";
	qcom,mdss-dsi-panel-status-command = [06 01 00 01 00 00 01 0a];
	qcom,mdss-dsi-panel-status-command-state = "dsi_lp_mode";
	qcom,mdss-dsi-panel-status-value = <0x1c>;
	qcom,mdss-dsi-panel-status-read-length = <1>;

	qcom_mdss_dsi_display_timings_324: qcom,mdss-dsi-display-timings {
		timing_0_325: timing@0 { /* 120 FPS */
			qcom,mdss-dsi-panel-phy-timings = [00 1a 07 06 16 15 07
				07 07 02 04 00 17 0c];
			qcom,display-topology = <4 4 2>;
			qcom,default-topology-index = <0>;
		};
	};
};

&dsi_sim_cmd {
	qcom,dsi-select-clocks = "pll_byte_clk0", "pll_dsi_clk0";
	qcom,poms-align-panel-vsync;
	qcom_mdss_dsi_display_timings_87: qcom,mdss-dsi-display-timings {
		timing_0_88: timing@0 { /* WQHD 60FPS cmd-vid mode*/
			qcom,mdss-dsi-panel-phy-timings = [00 1a 06 06 16 20 07
				07 07 02 04 00 16 0c];
			qcom,display-topology = <1 1 1>,
						<2 2 1>;
			qcom,default-topology-index = <1>;
			qcom,qsync-mode-min-refresh-rate = <50>;
		};

		timing_1_89: timing@1 { /* WQHD 60FPS vid mode*/
			qcom,mdss-dsi-panel-phy-timings = [00 1a 06 06 16 20 07
				07 07 02 04 00 16 0c];
			qcom,display-topology = <1 1 1>,
						<2 2 1>;
			qcom,default-topology-index = <1>;
			qcom,qsync-mode-min-refresh-rate = <50>;
		};

		timing_2_90: timing@2 { /* FHD+ 60FPS cmd mode*/
			qcom,mdss-dsi-panel-phy-timings = [00 25 0a 0a 1b 24 0a
				0a 0a 02 04 00 1f 0f];
			qcom,display-topology = <1 1 1>,
						<2 2 1>;
			qcom,default-topology-index = <1>;
			qcom,qsync-mode-min-refresh-rate = <10>;
		};

		timing_3_91: timing@3 { /* HD 60FPS cmd mode */
			qcom,mdss-dsi-panel-phy-timings = [00 29 0a 0b 1b 26 0a
				0b 0a 02 04 00 21 10];
			qcom,display-topology = <1 1 1>,
						<2 2 1>;
			qcom,default-topology-index = <1>;
			qcom,qsync-mode-min-refresh-rate = <48>;
		};

		timing_4_92: timing@4 { /* FHD+ 90FPS cmd mode*/
			qcom,mdss-dsi-panel-phy-timings = [00 39 0f 0e 21 2a 0e
				0f 0d 02 04 00 2d 13];
			qcom,display-topology = <1 1 1>,
						<2 2 1>;
			qcom,default-topology-index = <1>;
			qcom,qsync-mode-min-refresh-rate = <30>;
		};

		timing_5: timing@5 { /* FHD+ 180 FPS cmd mode*/
			qcom,mdss-dsi-panel-phy-timings = [00 69 1d 1d 35 2f 1b
				1d 18 02 04 00 51 21];
			qcom,display-topology = <2 2 1>;
			qcom,default-topology-index = <0>;
			qcom,qsync-mode-min-refresh-rate = <96>;
		};

		timing_6: timing@6 { /* FHD+ 240 FPS cmd mode*/
			qcom,mdss-dsi-panel-phy-timings = [00 89 26 27 42 39 25
				27 1f 02 04 00 69 2a];
			qcom,display-topology = <2 2 1>;
			qcom,default-topology-index = <0>;
			qcom,qsync-mode-min-refresh-rate = <110>;
		};

		timing_7: timing@7 { /* FHD+ 120FPS cmd mode*/
			qcom,mdss-dsi-panel-phy-timings = [00 4a 13 14 28 24 12
				14 11 02 04 00 39 18];
			qcom,display-topology = <1 1 1>,
						<2 2 1>;
			qcom,default-topology-index = <1>;
			qcom,qsync-mode-min-refresh-rate = <40>;
		};

		timing_8: timing@8 { /* FHD+ 144FPS cmd mode*/
			qcom,mdss-dsi-panel-phy-timings = [00 1a 06 06 16 20 07
				06 07 02 04 00 16 0b];
			qcom,display-topology = <1 1 1>,
						<2 2 1>;
			qcom,default-topology-index = <1>;
			qcom,qsync-mode-min-refresh-rate = <60>;
		};

		timing_9: timing@9 { /* WQHD 1FPS cmd mode*/
			qcom,mdss-dsi-panel-phy-timings = [00 18 06 06 15 20 06
				06 07 02 04 00 15 0b];
			qcom,display-topology = <1 1 1>,
						<2 2 1>;
			qcom,default-topology-index = <1>;
			qcom,qsync-mode-min-refresh-rate = <1>;
		};

		timing_10: timing@10 { /* WQHD 5FPS cmd mode*/
			qcom,mdss-dsi-panel-phy-timings = [00 18 06 06 15 20 06
				06 07 02 04 00 15 0b];
			qcom,display-topology = <1 1 1>,
						<2 2 1>;
			qcom,default-topology-index = <1>;
			qcom,qsync-mode-min-refresh-rate = <1>;
		};

		timing_11: timing@11 { /* WQHD 10FPS cmd mode*/
			qcom,mdss-dsi-panel-phy-timings = [00 18 06 06 15 20 06
				06 07 02 04 00 15 0b];
			qcom,display-topology = <1 1 1>,
						<2 2 1>;
			qcom,default-topology-index = <1>;
			qcom,qsync-mode-min-refresh-rate = <5>;
		};

		timing_12: timing@12 { /* WQHD 24FPS cmd mode*/
			qcom,mdss-dsi-panel-phy-timings = [00 18 06 06 15 20 06
				06 07 02 04 00 15 0b];
			qcom,display-topology = <1 1 1>,
						<2 2 1>;
			qcom,default-topology-index = <1>;
			qcom,qsync-mode-min-refresh-rate = <15>;
		};

		timing_13: timing@13 { /* WQHD 30FPS cmd mode*/
			qcom,mdss-dsi-panel-phy-timings = [00 18 06 06 15 20 06
				06 07 02 04 00 15 0b];
			qcom,display-topology = <1 1 1>,
						<2 2 1>;
			qcom,default-topology-index = <1>;
			qcom,qsync-mode-min-refresh-rate = <22>;
		};

		timing_14: timing@14 { /* WQHD 60FPS cmd mode*/
			qcom,mdss-dsi-panel-phy-timings = [00 18 06 06 15 20 06
				06 07 02 04 00 15 0b];
			qcom,display-topology = <1 1 1>,
						<2 2 1>;
			qcom,default-topology-index = <1>;
			qcom,qsync-mode-min-refresh-rate = <30>;
		};

		timing_15: timing@15 { /* WQHD 90FPS cmd mode*/
			qcom,mdss-dsi-panel-phy-timings = [00 22 09 09 19 23 09
				09 09 02 04 00 1d 0e];
			qcom,display-topology = <1 1 1>,
						<2 2 1>;
			qcom,default-topology-index = <1>;
			qcom,qsync-mode-min-refresh-rate = <10>;
		};

		timing_16: timing@16 { /* WQHD 120FPS cmd mode*/
			qcom,mdss-dsi-panel-phy-timings = [00 2c 0c 0c 1d 27 0c
				0c 0b 02 04 00 24 11];
			qcom,display-topology = <2 2 1>;
			qcom,default-topology-index = <0>;
			qcom,qsync-mode-min-refresh-rate = <1>;
		};

		timing_17: timing@17 { /* WQHD 144FPS cmd mode*/
			qcom,mdss-dsi-panel-phy-timings = [00 38 0e 0e 17 14 0e
				0e 0d 02 04 00 2b 12];
			qcom,display-topology = <2 2 1>;
			qcom,default-topology-index = <0>;
			qcom,qsync-mode-min-refresh-rate = <5>;
		};

		timing_18: timing@18 { /* WQHD 180FPS cmd mode*/
			qcom,mdss-dsi-panel-phy-timings = [00 3d 0f 0f 19 15 0f
				10 0e 02 04 00 2f 13];
			qcom,display-topology = <2 2 1>;
			qcom,default-topology-index = <0>;
			qcom,qsync-mode-min-refresh-rate = <30>;
		};

		timing_19: timing@19 { /* WQHD 165FPS cmd mode*/
			qcom,mdss-dsi-panel-phy-timings = [00 39 0e 0e 17 14 0e
				0e 0e 02 04 00 2c 11];
			qcom,display-topology = <2 2 1>;
			qcom,default-topology-index = <0>;
			qcom,qsync-mode-min-refresh-rate = <30>;
		};

		timing_20: timing@20 {
			qcom,mdss-dsi-panel-phy-timings = [00 3d 0f 0f 19 15 0f
				10 0e 02 04 00 2f 13];
			qcom,display-topology = <2 2 1>;
			qcom,default-topology-index = <0>;
			qcom,qsync-mode-min-refresh-rate = <30>;
		};
	};
};

&dsi_sim_vid {
	qcom,dsi-select-clocks = "pll_byte_clk0", "pll_dsi_clk0";
	qcom,dsi-supported-dfps-list = <144 120 90 60 30 10 1>;
	qcom,mdss-dsi-pan-enable-dynamic-fps;
	qcom,mdss-dsi-pan-fps-update = "dfps_immediate_porch_mode_vfp";

	qcom,qsync-enable;
	qcom,dsi-supported-qsync-min-fps-list = <1 1 1 1 1 1 1>;
	qcom,dsi-qsync-avr-step-list = <288 240 180 120 60 20 0>;

	qcom_mdss_dsi_display_timings_93: qcom,mdss-dsi-display-timings {
		timing_0_94: timing@0 {
			qcom,mdss-dsi-panel-phy-timings = [00 24 0a 0a 1a 24 0a
				0a 09 02 04 00 1e 0f];
			qcom,display-topology = <2 2 1>;
			qcom,default-topology-index = <0>;
		};
	};
};

&dsi_sim_dsc_375_cmd {
	qcom,dsi-select-clocks = "pll_byte_clk0", "pll_dsi_clk0";
	qcom_mdss_dsi_display_timings_95: qcom,mdss-dsi-display-timings {
		timing_0_96: timing@0 { /* 1080p */
			qcom,mdss-dsi-panel-phy-timings = [00 15 05 05 14 1f 05
				05 06 02 04 00 13 0a];
			qcom,display-topology = <1 1 1>;
			qcom,default-topology-index = <0>;
		};

		timing_1_97: timing@1 { /* qhd */
			qcom,mdss-dsi-panel-phy-timings = [00 0c 02 02 10 1c 03
				03 02 02 04 00 0b 08];
			qcom,display-topology = <1 1 1>,
						<2 2 1>, /* dsc merge */
						<2 1 1>; /* 3d mux */
			qcom,default-topology-index = <0>;
		};
	};
};

&dsi_sim_dsc_10b_cmd {
	qcom,dsi-select-clocks = "pll_byte_clk0", "pll_dsi_clk0";
	qcom_mdss_dsi_display_timings_98: qcom,mdss-dsi-display-timings {
		timing_0_99: timing@0 { /* QHD 60fps */
			qcom,mdss-dsi-panel-phy-timings = [00 15 05 05 14 1f 05
				05 06 02 04 00 13 0a];
			qcom,display-topology = <1 1 1>,
						<2 2 1>, /* dsc merge */
						<2 1 1>; /* 3d mux */
			qcom,default-topology-index = <1>;
		};

		timing_1_100: timing@1 { /* FHD+ 60fps cmd mode */
			qcom,mdss-dsi-panel-phy-timings = [00 0d 03 03 10 1d 03
				03 02 02 04 00 0c 08];
			qcom,display-topology = <1 1 1>,
						<2 2 1>, /* dsc merge */
						<2 1 1>; /* 3d mux */
			qcom,default-topology-index = <1>;
		};

		timing_2_101: timing@2 { /* QHD 90fps */
			qcom,mdss-dsi-panel-phy-timings = [00 1d 08 07 17 22 08
				08 08 02 04 00 19 0d];
			qcom,display-topology = <1 1 1>,
						<2 2 1>, /* dsc merge */
						<2 1 1>; /* 3d mux */
			qcom,default-topology-index = <1>;
		};

		timing_3_102: timing@3 { /* FHD+ 180FPS cmd mode*/
			qcom,mdss-dsi-panel-phy-timings = [00 1f 08 07 18 16 08
				08 08 02 04 00 1a 0d];
			qcom,display-topology = <2 2 1>;
			qcom,default-topology-index = <0>;
		};

		timing_4_103: timing@4 { /* FHD+ 240FPS cmd mode*/
			qcom,mdss-dsi-panel-phy-timings = [00 28 0a 0b 1b 1a 0a
				0b 0a 02 04 00 21 0f];
			qcom,display-topology = <2 2 1>;
			qcom,default-topology-index = <0>;
		};

		timing_5_104: timing@5 { /* FHD+ 120FPS cmd mode*/
			qcom,mdss-dsi-panel-phy-timings = [00 16 05 05 14 13 06
				06 06 02 04 00 13 0b];
			qcom,display-topology = <2 2 1>;
			qcom,default-topology-index = <0>;
		};

		timing_6_105: timing@6 { /* FHD+ 1FPS cmd mode*/
			qcom,mdss-dsi-panel-phy-timings = [03 04 00 00 0d 18 01
				00 01 02 04 00 05 05];
			qcom,display-topology = <1 1 1>,
						<2 2 1>;
			qcom,default-topology-index = <1>;
		};

		timing_7_106: timing@7 { /* FHD+ 10FPS cmd mode*/
			qcom,mdss-dsi-panel-phy-timings = [03 07 00 01 0d 1a 01
				01 01 02 04 00 07 06];
			qcom,display-topology = <1 1 1>,
						<2 2 1>;
			qcom,default-topology-index = <1>;
		};

		timing_8_107: timing@8 { /* FHD+ 24FPS cmd mode*/
			qcom,mdss-dsi-panel-phy-timings = [00 09 01 01 0e 1b 02
				01 01 02 04 00 08 06];
			qcom,display-topology = <1 1 1>,
						<2 2 1>;
			qcom,default-topology-index = <1>;
		};

		timing_9_108: timing@9 { /* FHD+ 30FPS cmd mode*/
			qcom,mdss-dsi-panel-phy-timings = [00 0a 01 02 0e 1b 02
				02 01 02 04 00 09 07];
			qcom,display-topology = <1 1 1>,
						<2 2 1>;
			qcom,default-topology-index = <1>;
		};

		timing_10_109: timing@10 { /* FHD+ 90FPS cmd mode*/
			qcom,mdss-dsi-panel-phy-timings = [00 39 0f 0e 21 2a 0e
				0f 0d 02 04 00 2d 13];
			qcom,display-topology = <2 2 1>;
			qcom,default-topology-index = <0>;
		};

		timing_11_110: timing@11 { /* FHD+ 144FPS cmd mode*/
			qcom,mdss-dsi-panel-phy-timings = [00 1a 06 06 16 20 07
				06 07 02 04 00 16 0b];
			qcom,display-topology = <2 2 1>;
			qcom,default-topology-index = <0>;
		};
	};
};

&dsi_dual_sim_cmd {
	qcom,dsi-select-clocks = "pll_byte_clk0", "pll_dsi_clk0";
	qcom_mdss_dsi_display_timings_111: qcom,mdss-dsi-display-timings {
		timing_0_112: timing@0 { /* 5K 60FPS cmd mode*/
			qcom,mdss-dsi-panel-phy-timings = [00 44 11 12 25 2d 11
				12 0f 02 04 00 35 16];
			qcom,display-topology = <2 0 2>;
			qcom,default-topology-index = <0>;
		};

		timing_1_113: timing@1 { /* FHD 120FPS cmd mode*/
			qcom,mdss-dsi-panel-phy-timings = [00 1c 07 07 17 15 07
				07 08 02 04 00 18 0c];
			qcom,display-topology = <2 0 2>;
			qcom,default-topology-index = <0>;
		};

		timing_2_114: timing@2 { /* WQHD 60FPS cmd mode*/
			qcom,mdss-dsi-panel-phy-timings = [00 1a 07 06 16 21 07
				07 07 02 04 00 17 0c];
			qcom,display-topology = <2 0 2>,
						<1 0 2>;
			qcom,default-topology-index = <0>;
		};

		timing_3_115: timing@3 { /* 4K 40FPS cmd mode*/
			qcom,mdss-dsi-panel-phy-timings = [00 25 0a 0a 1b 24 0a
				0a 0a 02 04 00 1f 0f];
			qcom,display-topology = <2 0 2>;
			qcom,default-topology-index = <0>;
		};

		timing_4_116: timing@4 { /* 5K 80FPS cmd mode*/
			qcom,mdss-dsi-panel-phy-timings = [00 57 17 17 2e 33 17
				18 14 02 04 00 43 1c];
			qcom,display-topology = <2 0 2>;
			qcom,default-topology-index = <0>;
		};

		timing_5_117: timing@5 { /* FHD 60FPS 24bpp cmd mode */
			qcom,mdss-dsi-panel-phy-timings = [00 13 05 04 13 1e 05
				05 06 02 04 00 12 0a];
			qcom,display-topology = <2 0 2>;
			qcom,default-topology-index = <0>;
		};

		timing_6_118: timing@6 { /* FHD 60FPS 30bpp cmd mode */
			qcom,mdss-dsi-panel-phy-timings = [00 17 06 05 15 20 06
				06 07 02 04 00 15 0b];
			qcom,display-topology = <2 0 2>;
			qcom,default-topology-index = <0>;
		};
	};
};

&dsi_dual_3840x2400_120hz_sim_vid {
	qcom,dsi-select-clocks = "pll_byte_clk0", "pll_dsi_clk0";

	qcom_mdss_dsi_display_timings_122: qcom,mdss-dsi-display-timings {
		timing_0_123: timing@0 {
			qcom,mdss-dsi-panel-phy-timings = [00 1a 07 06 16 21 07
				07 07 02 04 00 17 0c];
			qcom,display-topology = <2 2 2>;
			qcom,default-topology-index = <0>;
		};
	};
};

&dsi_dual_sim_dsc_375_cmd {
	qcom,dsi-select-clocks = "pll_byte_clk0", "pll_dsi_clk0";
	qcom_mdss_dsi_display_timings_124: qcom,mdss-dsi-display-timings {
		timing_0_125: timing@0 { /* 4k  30 FPS*/
			qcom,mdss-dsi-panel-phy-timings = [00 0e 03 03 11 1d 04
				04 03 02 04 00 0d 09];
			qcom,display-topology = <2 2 2>;
			qcom,default-topology-index = <0>;
		};

		timing_1_126: timing@1 { /* 4k  60 FPS*/
			qcom,mdss-dsi-panel-phy-timings = [00 18 06 06 15 20 06
				06 07 02 04 00 15 0b];
			qcom,display-topology = <2 2 2>;
			qcom,default-topology-index = <0>;
		};

		timing_2_127: timing@2 { /* 4k  90 FPS*/
			qcom,mdss-dsi-panel-phy-timings = [00 22 09 09 19 23 09
				09 09 02 04 00 1d 0e];
			qcom,display-topology = <2 2 2>;
			qcom,default-topology-index = <0>;
		};

		timing_3_128: timing@3 { /* 1080  30 FPS*/
			qcom,mdss-dsi-panel-phy-timings = [01 09 01 01 0e 1b 01
				01 02 02 04 00 08 06];
			qcom,display-topology = <2 2 2>;
			qcom,default-topology-index = <0>;
		};

		timing_4_129: timing@4 { /* 1080  60 FPS*/
			qcom,mdss-dsi-panel-phy-timings = [00 0b 02 02 0f 1c 03
				02 02 02 04 00 0a 07];
			qcom,display-topology = <2 2 2>;
			qcom,default-topology-index = <0>;
		};

		timing_5_130: timing@5 { /* 1080  90 FPS*/
			qcom,mdss-dsi-panel-phy-timings = [00 0e 03 03 11 1d 04
				03 03 02 04 00 0d 08];
			qcom,display-topology = <2 2 2>;
			qcom,default-topology-index = <0>;
		};

		timing_6_131: timing@6 { /* 1080  120 FPS*/
			qcom,mdss-dsi-panel-phy-timings = [00 11 04 04 12 12 04
				04 03 02 04 00 0f 09];
			qcom,display-topology = <2 2 2>;
			qcom,default-topology-index = <0>;
		};

		timing_7_132: timing@7 { /* qhd 30 FPS*/
			qcom,mdss-dsi-panel-phy-timings = [00 0a 02 02 0f 1c 02
				02 02 02 04 00 0a 07];
			qcom,display-topology = <2 2 2>;
			qcom,default-topology-index = <0>;
		};

		timing_8_133: timing@8 { /* qhd 60 FPS*/
			qcom,mdss-dsi-panel-phy-timings = [00 0f 03 03 11 1d 04
				04 03 02 04 00 0d 09];
			qcom,display-topology = <2 2 2>;
			qcom,default-topology-index = <0>;
		};

		timing_9_134: timing@9 { /* qhd  90 FPS*/
			qcom,mdss-dsi-panel-phy-timings = [00 14 05 05 13 1f 05
				05 06 02 04 00 12 0a];
			qcom,display-topology = <2 2 2>;
			qcom,default-topology-index = <0>;
		};

		timing_10_135: timing@10 { /* qhd 120 FPS*/
			qcom,mdss-dsi-panel-phy-timings = [00 19 06 06 15 14 07
				06 07 02 04 00 16 0b];
			qcom,display-topology = <2 2 2>;
			qcom,default-topology-index = <0>;
		};

		timing_11_136: timing@11 { /* 5k */
			qcom,mdss-dsi-panel-phy-timings = [00 1a 07 06 16 21 07
				07 07 02 04 00 17 0c];
			qcom,display-topology = <2 2 2>;
			qcom,default-topology-index = <0>;
		};

		timing_12_137: timing@12 { /* 720p 30 FPS */
			qcom,mdss-dsi-panel-phy-timings = [03 07 00 01 0d 1a 01
				01 01 02 04 00 07 06];
			qcom,display-topology = <2 2 2>;
			qcom,default-topology-index = <0>;
		};

		timing_13_138: timing@13 { /* 720p 60 FPS */
			qcom,mdss-dsi-panel-phy-timings = [01 09 01 01 0e 1b 01
				01 02 02 04 00 08 06];
			qcom,display-topology = <2 2 2>;
			qcom,default-topology-index = <0>;
		};

		timing_14_139: timing@14 { /* 720p 90 FPS */
			qcom,mdss-dsi-panel-phy-timings = [00 0a 02 02 0f 1c 02
				02 02 02 04 00 0a 07];
			qcom,display-topology = <2 2 2>;
			qcom,default-topology-index = <0>;
		};

		timing_15_140: timing@15 { /* 720 120 FPS */
			qcom,mdss-dsi-panel-phy-timings = [00 0b 02 02 0f 0f 03
				03 02 02 04 00 0a 08];
			qcom,display-topology = <2 2 2>;
			qcom,default-topology-index = <0>;
		};

		timing_16_141: timing@16 { /* 1080 144FPS cmd mode*/
			qcom,mdss-dsi-panel-phy-timings = [00 13 05 04 13 12 05
				05 06 02 04 00 12 0a];
			qcom,display-topology = <2 2 2>;
			qcom,default-topology-index = <0>;
		};

		timing_17_142: timing@17 { /* WQHD  144 FPS*/
			qcom,mdss-dsi-panel-phy-timings = [00 1d 07 07 17 16 07
				07 08 02 04 00 19 0c];
			qcom,display-topology = <2 2 2>;
			qcom,default-topology-index = <0>;
		};

		timing_18_119: timing@18 { /* 3840x2400 120FPS cmd mode */
			qcom,mdss-dsi-panel-phy-timings = [00 4b 14 14 29 24 13
				15 11 02 04 00 3a 19];
			qcom,display-topology = <2 2 2>;
			qcom,default-topology-index = <0>;
		};

		timing_19_120: timing@19 { /* 3200x2400 144FPS cmd mode */
			qcom,mdss-dsi-panel-phy-timings = [00 4b 14 14 29 24 13
				15 11 02 04 00 3a 19];
			qcom,display-topology = <2 2 2>;
			qcom,default-topology-index = <0>;
		};

		timing_20_121: timing@20 { /* 3000x2400 144FPS cmd mode */
			qcom,mdss-dsi-panel-phy-timings = [00 47 13 13 27 23 12
				13 10 02 04 00 38 17];
			qcom,display-topology = <2 2 2>;
			qcom,default-topology-index = <0>;
		};
	};
};

&dsi_sim_sec_hd_cmd {
	qcom,dsi-select-sec-clocks = "pll_byte_clk1", "pll_dsi_clk1";
	qcom_mdss_dsi_display_timings_143: qcom,mdss-dsi-display-timings {
		timing_0_144: timing@0 {
			qcom,mdss-dsi-panel-phy-timings = [00 10 04 04 12 1e
				04 04 03 02 04 00 0e 09];
			qcom,display-topology = <1 0 1>;
			qcom,default-topology-index = <0>;
		};
	};
};

&dsi_sim_256_cmd {
	qcom,dsi-select-clocks = "pll_byte_clk0", "pll_dsi_clk0";
	qcom,poms-align-panel-vsync;
	qcom_mdss_dsi_display_timings_333: qcom,mdss-dsi-display-timings {
		timing_0_333: timing@0 {
			qcom,mdss-dsi-panel-phy-timings = [00 1a 06 06 16 20 07
				07 07 02 04 00 16 0c];
			qcom,display-topology = <1 1 1>,
						<2 2 1>;
			qcom,default-topology-index = <1>;
			qcom,qsync-mode-min-refresh-rate = <50>;
		};

		timing_1_334: timing@1 {
			qcom,mdss-dsi-panel-phy-timings = [00 1a 06 06 16 20 07
				07 07 02 04 00 16 0c];
			qcom,display-topology = <1 1 1>,
						<2 2 1>;
			qcom,default-topology-index = <1>;
			qcom,qsync-mode-min-refresh-rate = <50>;
		};

		timing_2_335: timing@2 {
			qcom,mdss-dsi-panel-phy-timings = [00 25 0a 0a 1b 24 0a
				0a 0a 02 04 00 1f 0f];
			qcom,display-topology = <1 1 1>,
						<2 2 1>;
			qcom,default-topology-index = <1>;
			qcom,qsync-mode-min-refresh-rate = <10>;
		};

		timing_3_336: timing@3 {
			qcom,mdss-dsi-panel-phy-timings = [00 29 0a 0b 1b 26 0a
				0b 0a 02 04 00 21 10];
			qcom,display-topology = <1 1 1>,
						<2 2 1>;
			qcom,default-topology-index = <1>;
			qcom,qsync-mode-min-refresh-rate = <48>;
		};

		timing_4_337: timing@4 {
			qcom,mdss-dsi-panel-phy-timings = [00 39 0f 0e 21 2a 0e
				0f 0d 02 04 00 2d 13];
			qcom,display-topology = <1 1 1>,
						<2 2 1>;
			qcom,default-topology-index = <1>;
			qcom,qsync-mode-min-refresh-rate = <30>;
		};

		timing_5_338: timing@5 {
			qcom,mdss-dsi-panel-phy-timings = [00 69 1d 1d 35 2f 1b
				1d 18 02 04 00 51 21];
			qcom,display-topology = <2 2 1>;
			qcom,default-topology-index = <0>;
			qcom,qsync-mode-min-refresh-rate = <96>;
		};

		timing_6_339: timing@6 {
			qcom,mdss-dsi-panel-phy-timings = [00 89 26 27 42 39 25
				27 1f 02 04 00 69 2a];
			qcom,display-topology = <2 2 1>;
			qcom,default-topology-index = <0>;
			qcom,qsync-mode-min-refresh-rate = <110>;
		};

		timing_7_340: timing@7 {
			qcom,mdss-dsi-panel-phy-timings = [00 4a 13 14 28 24 12
				14 11 02 04 00 39 18];
			qcom,display-topology = <1 1 1>,
						<2 2 1>;
			qcom,default-topology-index = <1>;
			qcom,qsync-mode-min-refresh-rate = <40>;
		};

		timing_8_341: timing@8 {
			qcom,mdss-dsi-panel-phy-timings = [00 1a 06 06 16 20 07
				06 07 02 04 00 16 0b];
			qcom,display-topology = <1 1 1>,
						<2 2 1>;
			qcom,default-topology-index = <1>;
			qcom,qsync-mode-min-refresh-rate = <60>;
		};

		timing_9_342: timing@9 {
			qcom,mdss-dsi-panel-phy-timings = [00 18 06 06 15 20 06
				06 07 02 04 00 15 0b];
			qcom,display-topology = <1 1 1>,
						<2 2 1>;
			qcom,default-topology-index = <1>;
			qcom,qsync-mode-min-refresh-rate = <1>;
		};

		timing_10_343: timing@10 {
			qcom,mdss-dsi-panel-phy-timings = [00 18 06 06 15 20 06
				06 07 02 04 00 15 0b];
			qcom,display-topology = <1 1 1>,
						<2 2 1>;
			qcom,default-topology-index = <1>;
			qcom,qsync-mode-min-refresh-rate = <1>;
		};

		timing_11_344: timing@11 {
			qcom,mdss-dsi-panel-phy-timings = [00 18 06 06 15 20 06
				06 07 02 04 00 15 0b];
			qcom,display-topology = <1 1 1>,
						<2 2 1>;
			qcom,default-topology-index = <1>;
			qcom,qsync-mode-min-refresh-rate = <5>;
		};

		timing_12_345: timing@12 {
			qcom,mdss-dsi-panel-phy-timings = [00 18 06 06 15 20 06
				06 07 02 04 00 15 0b];
			qcom,display-topology = <1 1 1>,
						<2 2 1>;
			qcom,default-topology-index = <1>;
			qcom,qsync-mode-min-refresh-rate = <15>;
		};

		timing_13_346: timing@13 {
			qcom,mdss-dsi-panel-phy-timings = [00 18 06 06 15 20 06
				06 07 02 04 00 15 0b];
			qcom,display-topology = <1 1 1>,
						<2 2 1>;
			qcom,default-topology-index = <1>;
			qcom,qsync-mode-min-refresh-rate = <22>;
		};

		timing_14_347: timing@14 {
			qcom,mdss-dsi-panel-phy-timings = [00 18 06 06 15 20 06
				06 07 02 04 00 15 0b];
			qcom,display-topology = <1 1 1>,
						<2 2 1>;
			qcom,default-topology-index = <1>;
			qcom,qsync-mode-min-refresh-rate = <30>;
		};

		timing_15_348: timing@15 {
			qcom,mdss-dsi-panel-phy-timings = [00 22 09 09 19 23 09
				09 09 02 04 00 1d 0e];
			qcom,display-topology = <1 1 1>,
						<2 2 1>;
			qcom,default-topology-index = <1>;
			qcom,qsync-mode-min-refresh-rate = <10>;
		};

		timing_16_349: timing@16 {
			qcom,mdss-dsi-panel-phy-timings = [00 2c 0c 0c 1d 27 0c
				0c 0b 02 04 00 24 11];
			qcom,display-topology = <2 2 1>;
			qcom,default-topology-index = <0>;
			qcom,qsync-mode-min-refresh-rate = <1>;
		};

		timing_17_350: timing@17 {
			qcom,mdss-dsi-panel-phy-timings = [00 38 0e 0e 17 14 0e
				0e 0d 02 04 00 2b 12];
			qcom,display-topology = <2 2 1>;
			qcom,default-topology-index = <0>;
			qcom,qsync-mode-min-refresh-rate = <5>;
		};

		timing_18_351: timing@18 {
			qcom,mdss-dsi-panel-phy-timings = [00 3d 0f 0f 19 15 0f
				10 0e 02 04 00 2f 13];
			qcom,display-topology = <2 2 1>;
			qcom,default-topology-index = <0>;
			qcom,qsync-mode-min-refresh-rate = <30>;
		};

		timing_19_352: timing@19 {
			qcom,mdss-dsi-panel-phy-timings = [00 29 0a 0b 1b 26 0a
				0b 0a 02 04 00 21 10];
			qcom,display-topology = <1 1 1>,
						<2 2 1>;
			qcom,default-topology-index = <1>;
			qcom,qsync-mode-min-refresh-rate = <30>;
		};

		timing_20_353: timing@20 {
			qcom,mdss-dsi-panel-phy-timings = [00 29 0a 0b 1b 26 0a
				0b 0a 02 04 00 21 10];
			qcom,display-topology = <2 0 1>;
			qcom,default-topology-index = <0>;
			qcom,qsync-mode-min-refresh-rate = <30>;
		};

		timing_21_354: timing@21 {
			qcom,mdss-dsi-panel-phy-timings = [00 29 0a 0b 1b 26 0a
				0b 0a 02 04 00 21 10];
			qcom,display-topology = <2 0 1>;
			qcom,default-topology-index = <0>;
			qcom,qsync-mode-min-refresh-rate = <1>;
		};

		timing_22_355: timing@22 {
			qcom,mdss-dsi-panel-phy-timings = [00 29 0a 0b 1b 26 0a
				0b 0a 02 04 00 21 10];
			qcom,display-topology = <2 0 1>;
			qcom,default-topology-index = <0>;
			qcom,qsync-mode-min-refresh-rate = <1>;
		};

		timing_23_356: timing@23 {
			qcom,mdss-dsi-panel-phy-timings = [00 57 17 17 25 1f 17
				18 14 02 04 43 1b 00];
			qcom,display-topology = <2 0 1>;
			qcom,default-topology-index = <0>;
			qcom,qsync-mode-min-refresh-rate = <1>;
		};

		timing_24_357: timing@24 {
			qcom,mdss-dsi-panel-phy-timings = [00 53 16 16 23 1e 15
				16 13 02 04 40 19 00];
			qcom,display-topology = <2 0 1>;
			qcom,default-topology-index = <0>;
			qcom,qsync-mode-min-refresh-rate = <1>;
		};

		timing_25_358: timing@25 {
			qcom,mdss-dsi-panel-phy-timings = [00 44 11 12 1c 18 11
				12 0f 02 04 34 15 00];
			qcom,display-topology = <2 0 1>;
			qcom,default-topology-index = <0>;
			qcom,qsync-mode-min-refresh-rate = <1>;
		};

		timing_26_359: timing@26 {
			qcom,mdss-dsi-panel-phy-timings = [00 2c 0c 0c 1d 27 0c
				0c 0b 02 04 24 11 00];
			qcom,display-topology = <2 0 1>;
			qcom,default-topology-index = <0>;
			qcom,qsync-mode-min-refresh-rate = <1>;
		};

		timing_27_360: timing@27 {
			qcom,mdss-dsi-panel-phy-timings = [00 12 04 04 12 1e 04
				04 03 02 04 0f 09 00];
			qcom,display-topology = <2 0 1>;
			qcom,default-topology-index = <0>;
			qcom,qsync-mode-min-refresh-rate = <1>;
		};

		timing_28_361: timing@28 {
			qcom,mdss-dsi-panel-phy-timings = [00 59 18 18 26 20 17
				18 14 02 04 44 1b 00];
			qcom,display-topology = <2 0 1>;
			qcom,default-topology-index = <0>;
			qcom,qsync-mode-min-refresh-rate = <1>;
		};

		timing_29_362: timing@29 {
			qcom,mdss-dsi-panel-phy-timings = [00 49 13 13 1f 1b 12
				14 11 02 04 38 17 00];
			qcom,display-topology = <2 0 1>;
			qcom,default-topology-index = <0>;
			qcom,qsync-mode-min-refresh-rate = <1>;
		};

		timing_30_363: timing@30 {
			qcom,mdss-dsi-panel-phy-timings = [00 39 0f 0e 18 15 0e
				0f 0d 02 04 2c 12 00];
			qcom,display-topology = <2 0 1>;
			qcom,default-topology-index = <0>;
			qcom,qsync-mode-min-refresh-rate = <1>;
		};

		timing_31_364: timing@31 {
			qcom,mdss-dsi-panel-phy-timings = [00 25 0a 0a 1b 24 0a
				0a 0a 02 04 1f 0f 00];
			qcom,display-topology = <2 0 1>;
			qcom,default-topology-index = <0>;
			qcom,qsync-mode-min-refresh-rate = <1>;
		};

		timing_32_365: timing@32 {
			qcom,mdss-dsi-panel-phy-timings = [00 10 03 03 11 1e 04
				04 03 02 04 0e 09 00];
			qcom,display-topology = <2 0 1>;
			qcom,default-topology-index = <0>;
			qcom,qsync-mode-min-refresh-rate = <1>;
		};

		timing_33_366: timing@33 {
			qcom,mdss-dsi-panel-phy-timings = [00 64 1b 1b 2b 24 1a
				1b 17 02 04 4d 1e 00];
			qcom,display-topology = <2 0 1>;
			qcom,default-topology-index = <0>;
			qcom,qsync-mode-min-refresh-rate = <1>;
		};

		timing_34_367: timing@34 {
			qcom,mdss-dsi-panel-phy-timings = [00 43 11 12 1c 18 11
				12 0f 02 04 33 15 00];
			qcom,display-topology = <2 0 1>;
			qcom,default-topology-index = <0>;
			qcom,qsync-mode-min-refresh-rate = <1>;
		};

		timing_35_368: timing@35 {
			qcom,mdss-dsi-panel-phy-timings = [00 46 12 13 1d 19 12
				13 10 02 04 36 16 00];
			qcom,display-topology = <2 0 1>;
			qcom,default-topology-index = <0>;
			qcom,qsync-mode-min-refresh-rate = <1>;
		};

		timing_36_369: timing@36 {
			qcom,mdss-dsi-panel-phy-timings = [00 38 0e 0e 17 14 0e
				0e 0d 02 04 2b 12 00];
			qcom,display-topology = <2 0 1>;
			qcom,default-topology-index = <0>;
			qcom,qsync-mode-min-refresh-rate = <1>;
		};

		timing_37_370: timing@37 {
			qcom,mdss-dsi-panel-phy-timings = [00 37 0e 0e 17 14 0d
				0e 0d 02 04 2b 11 00];
			qcom,display-topology = <2 0 1>;
			qcom,default-topology-index = <0>;
			qcom,qsync-mode-min-refresh-rate = <1>;
		};

		timing_38_371: timing@38 {
			qcom,mdss-dsi-panel-phy-timings = [00 29 0a 0b 1b 26 0a
				0b 0a 02 04 21 10 00];
			qcom,display-topology = <2 0 1>;
			qcom,default-topology-index = <0>;
			qcom,qsync-mode-min-refresh-rate = <1>;
		};

		timing_39_372: timing@39 {
			qcom,mdss-dsi-panel-phy-timings = [00 24 09 09 1a 24 09
				09 09 02 04 1e 0e 00];
			qcom,display-topology = <2 0 1>;
			qcom,default-topology-index = <0>;
			qcom,qsync-mode-min-refresh-rate = <1>;
		};

		timing_40_373: timing@40 {
			qcom,mdss-dsi-panel-phy-timings = [00 1c 07 07 17 22 07
				07 08 02 04 18 0c 00];
			qcom,display-topology = <2 0 1>;
			qcom,default-topology-index = <0>;
			qcom,qsync-mode-min-refresh-rate = <1>;
		};

		timing_41_374: timing@41 {
			qcom,mdss-dsi-panel-phy-timings = [00 40 11 11 1b 17 10
				11 0f 02 04 32 14 00];
			qcom,display-topology = <2 0 1>;
			qcom,default-topology-index = <0>;
			qcom,qsync-mode-min-refresh-rate = <1>;
		};

		timing_42_375: timing@42 {
			qcom,mdss-dsi-panel-phy-timings = [00 38 0e 0e 17 13 0e
				0e 0d 02 04 2b 12 00];
			qcom,display-topology = <2 0 1>;
			qcom,default-topology-index = <0>;
			qcom,qsync-mode-min-refresh-rate = <1>;
		};

		timing_43_376: timing@43 {
			qcom,mdss-dsi-panel-phy-timings = [00 21 08 08 19 23 09
				08 09 02 04 1c 0d 00];
			qcom,display-topology = <2 0 1>;
			qcom,default-topology-index = <0>;
			qcom,qsync-mode-min-refresh-rate = <1>;
		};

		timing_44_377: timing@44 {
			qcom,mdss-dsi-panel-phy-timings = [00 17 06 05 15 20 06
				06 07 02 04 15 0b 00];
			qcom,display-topology = <2 0 1>;
			qcom,default-topology-index = <0>;
			qcom,qsync-mode-min-refresh-rate = <1>;
		};

		timing_45_378: timing@45 {
			qcom,mdss-dsi-panel-phy-timings = [00 0b 02 02 0f 1c 03
				02 02 02 04 0a 07 00];
			qcom,display-topology = <2 0 1>;
			qcom,default-topology-index = <0>;
			qcom,qsync-mode-min-refresh-rate = <1>;
		};

		timing_46_379: timing@46 {
			qcom,mdss-dsi-panel-phy-timings = [00 42 11 11 1c 17 11
				11 0f 02 04 33 14 00];
			qcom,display-topology = <2 0 1>;
			qcom,default-topology-index = <0>;
			qcom,qsync-mode-min-refresh-rate = <1>;
		};

		timing_47_380: timing@47 {
			qcom,mdss-dsi-panel-phy-timings = [00 3a 0e 0e 18 14 0e
				0f 0d 02 04 2c 12 00];
			qcom,display-topology = <2 0 1>;
			qcom,default-topology-index = <0>;
			qcom,qsync-mode-min-refresh-rate = <1>;
		};

		timing_48_381: timing@48 {
			qcom,mdss-dsi-panel-phy-timings = [00 22 08 09 19 23 09
				09 09 02 04 1c 0e 00];
			qcom,display-topology = <2 0 1>;
			qcom,default-topology-index = <0>;
			qcom,qsync-mode-min-refresh-rate = <1>;
		};

		timing_49_382: timing@49 {
			qcom,mdss-dsi-panel-phy-timings = [00 18 06 06 15 20 06
				06 07 02 04 15 0b 00];
			qcom,display-topology = <2 0 1>;
			qcom,default-topology-index = <0>;
			qcom,qsync-mode-min-refresh-rate = <1>;
		};

		timing_50_383: timing@50 {
			qcom,mdss-dsi-panel-phy-timings = [00 47 13 13 1e 1a 12
				14 10 02 04 37 17 00];
			qcom,display-topology = <2 0 1>;
			qcom,default-topology-index = <0>;
			qcom,qsync-mode-min-refresh-rate = <1>;
		};

		timing_51_384: timing@51 {
			qcom,mdss-dsi-panel-phy-timings = [00 2f 0d 0d 1e 27 0c
				0d 0c 02 04 27 11 00];
			qcom,display-topology = <2 0 1>;
			qcom,default-topology-index = <0>;
			qcom,qsync-mode-min-refresh-rate = <1>;
		};

		timing_52_385: timing@52 {
			qcom,mdss-dsi-panel-phy-timings = [00 24 0a 0a 1a 24 0a
				0a 09 02 04 1e 0f 00];
			qcom,display-topology = <2 0 1>;
			qcom,default-topology-index = <0>;
			qcom,qsync-mode-min-refresh-rate = <1>;
		};

		timing_53_386: timing@53 {
			qcom,mdss-dsi-panel-phy-timings = [00 3f 10 10 1a 16 10
				10 0e 02 04 30 14 00];
			qcom,display-topology = <2 0 1>;
			qcom,default-topology-index = <0>;
			qcom,qsync-mode-min-refresh-rate = <1>;
		};

		timing_54_387: timing@54 {
			qcom,mdss-dsi-panel-phy-timings = [00 29 0b 0b 1b 26 0b
				0b 0a 02 04 22 10 00];
			qcom,display-topology = <2 0 1>;
			qcom,default-topology-index = <0>;
			qcom,qsync-mode-min-refresh-rate = <1>;
		};

		timing_55_388: timing@55 {
			qcom,mdss-dsi-panel-phy-timings = [00 20 08 08 18 23 08
				08 08 02 04 1b 0d 00];
			qcom,display-topology = <2 0 1>;
			qcom,default-topology-index = <0>;
			qcom,qsync-mode-min-refresh-rate = <1>;
		};

		timing_56_389: timing@56 {
			qcom,mdss-dsi-panel-phy-timings = [00 16 06 05 14 1f 06
				06 06 02 04 14 0b 00];
			qcom,display-topology = <2 0 1>;
			qcom,default-topology-index = <0>;
			qcom,qsync-mode-min-refresh-rate = <1>;
		};

		timing_57_390: timing@57 {
			qcom,mdss-dsi-panel-phy-timings = [00 25 0a 0a 1b 24 0a
				0a 0a 02 04 1f 0f 00];
			qcom,display-topology = <2 0 1>;
			qcom,default-topology-index = <0>;
			qcom,qsync-mode-min-refresh-rate = <1>;
		};

		timing_58_391: timing@58 {
			qcom,mdss-dsi-panel-phy-timings = [00 1f 08 07 18 23 08
				08 08 02 04 1a 0d 00];
			qcom,display-topology = <2 0 1>;
			qcom,default-topology-index = <0>;
			qcom,qsync-mode-min-refresh-rate = <1>;
		};

		timing_59_392: timing@59 {
			qcom,mdss-dsi-panel-phy-timings = [00 1f 08 07 18 22 08
				08 08 02 04 1a 0d 00];
			qcom,display-topology = <2 0 1>;
			qcom,default-topology-index = <0>;
			qcom,qsync-mode-min-refresh-rate = <1>;
		};

		timing_60_393: timing@60 {
			qcom,mdss-dsi-panel-phy-timings = [00 40 10 11 1b 17 10
				11 0f 02 04 31 14 00];
			qcom,display-topology = <2 0 1>;
			qcom,default-topology-index = <0>;
			qcom,qsync-mode-min-refresh-rate = <1>;
		};

		timing_61_394: timing@61 {
			qcom,mdss-dsi-panel-phy-timings = [00 37 0e 0e 17 14 0d
				0e 0d 02 04 2b 11 00];
			qcom,display-topology = <2 0 1>;
			qcom,default-topology-index = <0>;
			qcom,qsync-mode-min-refresh-rate = <1>;
		};

		timing_62_395: timing@62 {
			qcom,mdss-dsi-panel-phy-timings = [00 2a 0b 0b 1c 26 0b
				0c 0b 02 04 23 10 00];
			qcom,display-topology = <2 0 1>;
			qcom,default-topology-index = <0>;
			qcom,qsync-mode-min-refresh-rate = <1>;
		};

		timing_63_396: timing@63 {
			qcom,mdss-dsi-panel-phy-timings = [00 21 08 08 19 22 09
				08 09 02 04 1c 0d 00];
			qcom,display-topology = <2 0 1>;
			qcom,default-topology-index = <0>;
			qcom,qsync-mode-min-refresh-rate = <1>;
		};

		timing_64_397: timing@64 {
			qcom,mdss-dsi-panel-phy-timings = [00 17 06 05 15 1f 06
				06 07 02 04 15 0b 00];
			qcom,display-topology = <2 0 1>;
			qcom,default-topology-index = <0>;
			qcom,qsync-mode-min-refresh-rate = <1>;
		};

		timing_65_398: timing@65 {
			qcom,mdss-dsi-panel-phy-timings = [00 0b 02 02 0f 1c 03
				02 02 02 04 0a 07 00];
			qcom,display-topology = <2 0 1>;
			qcom,default-topology-index = <0>;
			qcom,qsync-mode-min-refresh-rate = <1>;
		};

		timing_66_399: timing@66 {
			qcom,mdss-dsi-panel-phy-timings = [00 3c 0f 0f 19 15 0f
				0f 0e 02 04 2e 13 00];
			qcom,display-topology = <2 0 1>;
			qcom,default-topology-index = <0>;
			qcom,qsync-mode-min-refresh-rate = <1>;
		};

		timing_67_400: timing@67 {
			qcom,mdss-dsi-panel-phy-timings = [00 2c 0b 0c 1c 26 0c
				0c 0b 02 04 24 10 00];
			qcom,display-topology = <2 0 1>;
			qcom,default-topology-index = <0>;
			qcom,qsync-mode-min-refresh-rate = <1>;
		};

		timing_68_401: timing@68 {
			qcom,mdss-dsi-panel-phy-timings = [00 35 0d 0d 16 12 0d
				0d 0c 02 04 29 11 00];
			qcom,display-topology = <2 0 1>;
			qcom,default-topology-index = <0>;
			qcom,qsync-mode-min-refresh-rate = <1>;
		};

		timing_69_402: timing@69 {
			qcom,mdss-dsi-panel-phy-timings = [00 29 0b 0b 1b 26 0b
				0c 0a 02 04 22 10 00];
			qcom,display-topology = <2 0 1>;
			qcom,default-topology-index = <0>;
			qcom,qsync-mode-min-refresh-rate = <1>;
		};

		timing_70_403: timing@70 {
			qcom,mdss-dsi-panel-phy-timings = [00 1e 08 07 18 22 08
				08 08 02 04 1a 0d 00];
			qcom,display-topology = <2 0 1>;
			qcom,default-topology-index = <0>;
			qcom,qsync-mode-min-refresh-rate = <1>;
		};

		timing_71_404: timing@71 {
			qcom,mdss-dsi-panel-phy-timings = [00 22 09 09 19 23 09
				09 09 02 04 1d 0e 00];
			qcom,display-topology = <2 0 1>;
			qcom,default-topology-index = <0>;
			qcom,qsync-mode-min-refresh-rate = <1>;
		};

		timing_72_405: timing@72 {
			qcom,mdss-dsi-panel-phy-timings = [00 18 06 06 15 20 06
				06 07 02 04 15 0b 00];
			qcom,display-topology = <2 0 1>;
			qcom,default-topology-index = <0>;
			qcom,qsync-mode-min-refresh-rate = <1>;
		};

		timing_73_406: timing@73 {
			qcom,mdss-dsi-panel-phy-timings = [00 13 04 04 13 1e 05
				05 06 02 04 11 0a 00];
			qcom,display-topology = <2 0 1>;
			qcom,default-topology-index = <0>;
			qcom,qsync-mode-min-refresh-rate = <1>;
		};

		timing_74_407: timing@74 {
			qcom,mdss-dsi-panel-phy-timings = [00 11 04 04 12 1e 04
				04 03 02 04 0f 09 00];
			qcom,display-topology = <2 0 1>;
			qcom,default-topology-index = <0>;
			qcom,qsync-mode-min-refresh-rate = <1>;
		};

		timing_75_408: timing@75 {
			qcom,mdss-dsi-panel-phy-timings = [00 13 05 04 13 1e 05
				05 06 02 04 12 0a 00];
			qcom,display-topology = <2 0 1>;
			qcom,default-topology-index = <0>;
			qcom,qsync-mode-min-refresh-rate = <1>;
		};

		timing_76_409: timing@76 {
			qcom,mdss-dsi-panel-phy-timings = [00 11 04 04 12 1e 04
				04 03 02 04 0f 09 00];
			qcom,display-topology = <2 0 1>;
			qcom,default-topology-index = <0>;
			qcom,qsync-mode-min-refresh-rate = <1>;
		};

		timing_77_410: timing@77 {
			qcom,mdss-dsi-panel-phy-timings = [00 0a 01 02 0e 1c 02
				02 01 02 04 09 07 00];
			qcom,display-topology = <2 0 1>;
			qcom,default-topology-index = <0>;
			qcom,qsync-mode-min-refresh-rate = <1>;
		};

		timing_78_411: timing@78 {
			qcom,mdss-dsi-panel-phy-timings = [00 0a 02 02 0f 1c 02
				02 02 02 04 0a 07 00];
			qcom,display-topology = <2 0 1>;
			qcom,default-topology-index = <0>;
			qcom,qsync-mode-min-refresh-rate = <1>;
		};

		timing_79_412: timing@79 {
			qcom,mdss-dsi-panel-phy-timings = [03 08 00 01 0d 1b 01
				01 01 02 04 07 06 00];
			qcom,display-topology = <2 0 1>;
			qcom,default-topology-index = <0>;
			qcom,qsync-mode-min-refresh-rate = <1>;
		};

		timing_80_413: timing@80 {
			qcom,mdss-dsi-panel-phy-timings = [00 2b 0c 0c 1c 26 0c
				0c 0b 02 04 24 10 00];
			qcom,display-topology = <2 0 1>;
			qcom,default-topology-index = <0>;
			qcom,qsync-mode-min-refresh-rate = <1>;
		};

		timing_81_414: timing@81 {
			qcom,mdss-dsi-panel-phy-timings = [00 1e 08 07 18 22 08
				08 08 02 04 1a 0d 00];
			qcom,display-topology = <2 0 1>;
			qcom,default-topology-index = <0>;
			qcom,qsync-mode-min-refresh-rate = <1>;
		};

		timing_82_415: timing@82 {
			qcom,mdss-dsi-panel-phy-timings = [00 0a 01 02 0e 1b 02
				02 01 02 04 09 07 00];
			qcom,display-topology = <2 0 1>;
			qcom,default-topology-index = <0>;
			qcom,qsync-mode-min-refresh-rate = <1>;
		};

		timing_83_416: timing@83 {
			qcom,mdss-dsi-panel-phy-timings = [00 24 0a 0a 1a 24 0a
				0a 09 02 04 1e 0f 00];
			qcom,display-topology = <2 0 1>;
			qcom,default-topology-index = <0>;
			qcom,qsync-mode-min-refresh-rate = <1>;
		};

		timing_84_417: timing@84 {
			qcom,mdss-dsi-panel-phy-timings = [00 0f 03 03 11 1d 04
				04 03 02 04 0d 09 00];
			qcom,display-topology = <2 0 1>;
			qcom,default-topology-index = <0>;
			qcom,qsync-mode-min-refresh-rate = <1>;
		};

		timing_85_418: timing@85 {
			qcom,mdss-dsi-panel-phy-timings = [00 09 01 01 0e 1b 02
				01 01 02 04 08 06 00];
			qcom,display-topology = <2 0 1>;
			qcom,default-topology-index = <0>;
			qcom,qsync-mode-min-refresh-rate = <1>;
		};

		timing_86_419: timing@86 {
			qcom,mdss-dsi-panel-phy-timings = [00 22 08 09 19 23 09
				09 09 02 04 1c 0e 00];
			qcom,display-topology = <2 0 1>;
			qcom,default-topology-index = <0>;
			qcom,qsync-mode-min-refresh-rate = <1>;
		};

		timing_87_420: timing@87 {
			qcom,mdss-dsi-panel-phy-timings = [00 1d 07 07 17 22 07
				07 08 02 04 19 0c 00];
			qcom,display-topology = <2 0 1>;
			qcom,default-topology-index = <0>;
			qcom,qsync-mode-min-refresh-rate = <1>;
		};

		timing_88_421: timing@88 {
			qcom,mdss-dsi-panel-phy-timings = [00 18 06 06 15 20 06
				06 07 02 04 15 0b 00];
			qcom,display-topology = <2 0 1>;
			qcom,default-topology-index = <0>;
			qcom,qsync-mode-min-refresh-rate = <1>;
		};

		timing_89_422: timing@89 {
			qcom,mdss-dsi-panel-phy-timings = [00 14 05 05 13 1f 05
				05 06 02 04 12 0a 00];
			qcom,display-topology = <2 0 1>;
			qcom,default-topology-index = <0>;
			qcom,qsync-mode-min-refresh-rate = <1>;
		};

		timing_90_423: timing@90 {
			qcom,mdss-dsi-panel-phy-timings = [00 13 04 04 13 1e 05
				05 06 02 04 11 0a 00];
			qcom,display-topology = <2 0 1>;
			qcom,default-topology-index = <0>;
			qcom,qsync-mode-min-refresh-rate = <1>;
		};

		timing_91_424: timing@91 {
			qcom,mdss-dsi-panel-phy-timings = [00 0e 03 03 11 1d 04
				04 03 02 04 0d 09 00];
			qcom,display-topology = <2 0 1>;
			qcom,default-topology-index = <0>;
			qcom,qsync-mode-min-refresh-rate = <1>;
		};

		timing_92_425: timing@92 {
			qcom,mdss-dsi-panel-phy-timings = [01 09 01 01 0e 1b 01
				01 02 02 04 08 06 00];
			qcom,display-topology = <2 0 1>;
			qcom,default-topology-index = <0>;
			qcom,qsync-mode-min-refresh-rate = <1>;
		};

		timing_93_426: timing@93 {
			qcom,mdss-dsi-panel-phy-timings = [00 77 21 21 33 2b 1f
				21 1b 02 04 5b 24 00];
			qcom,display-topology = <2 0 1>;
			qcom,default-topology-index = <0>;
			qcom,qsync-mode-min-refresh-rate = <1>;
		};

		timing_94_427: timing@94 {
			qcom,mdss-dsi-panel-phy-timings = [00 28 0a 0b 1b 26 0a
				0b 0a 02 04 21 0f 00];
			qcom,display-topology = <2 0 1>;
			qcom,default-topology-index = <0>;
			qcom,qsync-mode-min-refresh-rate = <1>;
		};

		timing_95_428: timing@95 {
			qcom,mdss-dsi-panel-phy-timings = [00 53 16 16 23 1e 15
				16 13 02 04 40 19 00];
			qcom,display-topology = <2 0 1>;
			qcom,default-topology-index = <0>;
			qcom,qsync-mode-min-refresh-rate = <1>;
		};

		timing_96_429: timing@96 {
			qcom,mdss-dsi-panel-phy-timings = [00 1c 07 07 17 22 07
				07 08 02 04 18 0c 00];
			qcom,display-topology = <2 0 1>;
			qcom,default-topology-index = <0>;
			qcom,qsync-mode-min-refresh-rate = <1>;
		};

		timing_97_430: timing@97 {
			qcom,mdss-dsi-panel-phy-timings = [00 40 11 11 1b 17 10
				11 0f 02 04 32 14 00];
			qcom,display-topology = <2 0 1>;
			qcom,default-topology-index = <0>;
			qcom,qsync-mode-min-refresh-rate = <1>;
		};

		timing_98_431: timing@98 {
			qcom,mdss-dsi-panel-phy-timings = [00 17 05 05 14 1f 06
				06 06 02 04 14 0b 00];
			qcom,display-topology = <2 0 1>;
			qcom,default-topology-index = <0>;
			qcom,qsync-mode-min-refresh-rate = <1>;
		};

		timing_99_432: timing@99 {
			qcom,mdss-dsi-panel-phy-timings = [00 2a 0b 0b 1c 26 0b
				0c 0b 02 04 23 10 00];
			qcom,display-topology = <2 0 1>;
			qcom,default-topology-index = <0>;
			qcom,qsync-mode-min-refresh-rate = <1>;
		};

		timing_100_433: timing@100 {
			qcom,mdss-dsi-panel-phy-timings = [00 11 03 04 12 1e 04
				04 03 02 04 0e 09 00];
			qcom,display-topology = <2 0 1>;
			qcom,default-topology-index = <0>;
			qcom,qsync-mode-min-refresh-rate = <1>;
		};

		timing_101_434: timing@101 {
			qcom,mdss-dsi-panel-phy-timings = [00 11 04 04 12 1e 04
				04 03 02 04 0f 09 00];
			qcom,display-topology = <2 0 1>;
			qcom,default-topology-index = <0>;
			qcom,qsync-mode-min-refresh-rate = <1>;
		};

		timing_102_435: timing@102 {
			qcom,mdss-dsi-panel-phy-timings = [00 0a 01 01 0e 1b 02
				01 01 02 04 09 06 00];
			qcom,display-topology = <2 0 1>;
			qcom,default-topology-index = <0>;
			qcom,qsync-mode-min-refresh-rate = <1>;
		};

		timing_103_436: timing@103 {
			qcom,mdss-dsi-panel-phy-timings = [00 1f 08 07 18 22 08
				08 08 02 04 1a 0d 00];
			qcom,display-topology = <2 0 1>;
			qcom,default-topology-index = <0>;
			qcom,qsync-mode-min-refresh-rate = <1>;
		};

		timing_104_437: timing@104 {
			qcom,mdss-dsi-panel-phy-timings = [00 1c 07 07 17 22 07
				07 08 02 04 18 0c 00];
			qcom,display-topology = <2 0 1>;
			qcom,default-topology-index = <0>;
			qcom,qsync-mode-min-refresh-rate = <1>;
		};

		timing_105_438: timing@105 {
			qcom,mdss-dsi-panel-phy-timings = [00 73 1f 20 31 2a 1e
				20 1a 02 04 58 22 00];
			qcom,display-topology = <2 0 1>;
			qcom,default-topology-index = <0>;
			qcom,qsync-mode-min-refresh-rate = <1>;
		};

		timing_106_439: timing@106 {
			qcom,mdss-dsi-panel-phy-timings = [00 70 1f 1f 30 29 1d
				1f 19 02 04 56 22 00];
			qcom,display-topology = <2 0 1>;
			qcom,default-topology-index = <0>;
			qcom,qsync-mode-min-refresh-rate = <1>;
		};

		timing_107_440: timing@107 {
			qcom,mdss-dsi-panel-phy-timings = [00 51 15 15 22 1c 15
				16 12 02 04 3e 19 00];
			qcom,display-topology = <2 0 1>;
			qcom,default-topology-index = <0>;
			qcom,qsync-mode-min-refresh-rate = <1>;
		};

		timing_108_441: timing@108 {
			qcom,mdss-dsi-panel-phy-timings = [00 4f 15 15 21 1d 14
				16 12 02 04 3d 19 00];
			qcom,display-topology = <2 0 1>;
			qcom,default-topology-index = <0>;
			qcom,qsync-mode-min-refresh-rate = <1>;
		};

		timing_109_442: timing@109 {
			qcom,mdss-dsi-panel-phy-timings = [00 3f 10 10 1a 16 10
				10 0e 02 04 30 14 00];
			qcom,display-topology = <2 0 1>;
			qcom,default-topology-index = <0>;
			qcom,qsync-mode-min-refresh-rate = <1>;
		};

		timing_110_443: timing@110 {
			qcom,mdss-dsi-panel-phy-timings = [00 3e 0f 0f 19 16 0f
				10 0e 02 04 2f 13 00];
			qcom,display-topology = <2 0 1>;
			qcom,default-topology-index = <0>;
			qcom,qsync-mode-min-refresh-rate = <1>;
		};

		timing_111_444: timing@111 {
			qcom,mdss-dsi-panel-phy-timings = [00 20 08 08 18 23 08
				08 08 02 04 1b 0d 00];
			qcom,display-topology = <2 0 1>;
			qcom,default-topology-index = <0>;
			qcom,qsync-mode-min-refresh-rate = <1>;
		};

		timing_112_445: timing@112 {
			qcom,mdss-dsi-panel-phy-timings = [00 16 06 05 14 1f 06
				06 06 02 04 14 0b 00];
			qcom,display-topology = <2 0 1>;
			qcom,default-topology-index = <0>;
			qcom,qsync-mode-min-refresh-rate = <1>;
		};

		timing_113_446: timing@113 {
			qcom,mdss-dsi-panel-phy-timings = [00 0d 03 03 10 1d 04
				03 02 02 04 0c 08 00];
			qcom,display-topology = <2 0 1>;
			qcom,default-topology-index = <0>;
			qcom,qsync-mode-min-refresh-rate = <1>;
		};

		timing_114_447: timing@114 {
			qcom,mdss-dsi-panel-phy-timings = [00 17 05 05 14 1f 06
				06 06 02 04 14 0b 00];
			qcom,display-topology = <2 0 1>;
			qcom,default-topology-index = <0>;
			qcom,qsync-mode-min-refresh-rate = <1>;
		};

		timing_115_448: timing@115 {
			qcom,mdss-dsi-panel-phy-timings = [00 29 0b 0b 1b 26 0b
				0b 0a 02 04 22 10 00];
			qcom,display-topology = <2 0 1>;
			qcom,default-topology-index = <0>;
			qcom,qsync-mode-min-refresh-rate = <1>;
		};

		timing_116_449: timing@116 {
			qcom,mdss-dsi-panel-phy-timings = [00 1d 08 07 17 22 07
				07 08 02 04 19 0c 00];
			qcom,display-topology = <2 0 1>;
			qcom,default-topology-index = <0>;
			qcom,qsync-mode-min-refresh-rate = <1>;
		};

		timing_117_450: timing@117 {
			qcom,mdss-dsi-panel-phy-timings = [00 19 06 06 15 20 07
				06 07 02 04 16 0b 00];
			qcom,display-topology = <2 0 1>;
			qcom,default-topology-index = <0>;
			qcom,qsync-mode-min-refresh-rate = <1>;
		};

		timing_118_451: timing@118 {
			qcom,mdss-dsi-panel-phy-timings = [00 1c 08 07 17 22 07
				07 08 02 04 19 0c 00];
			qcom,display-topology = <2 0 1>;
			qcom,default-topology-index = <0>;
			qcom,qsync-mode-min-refresh-rate = <1>;
		};

		timing_119_452: timing@119 {
			qcom,mdss-dsi-panel-phy-timings = [00 0e 03 03 11 1d 04
				04 03 02 04 0d 09 00];
			qcom,display-topology = <2 0 1>;
			qcom,default-topology-index = <0>;
			qcom,qsync-mode-min-refresh-rate = <1>;
		};

		timing_120_453: timing@120 {
			qcom,mdss-dsi-panel-phy-timings = [00 11 04 04 12 1e 04
				04 03 02 04 0f 09 00];
			qcom,display-topology = <2 0 1>;
			qcom,default-topology-index = <0>;
			qcom,qsync-mode-min-refresh-rate = <1>;
		};

		timing_121_454: timing@121 {
			qcom,mdss-dsi-panel-phy-timings = [00 16 05 05 14 1f 06
				06 06 02 04 13 0b 00];
			qcom,display-topology = <2 0 1>;
			qcom,default-topology-index = <0>;
			qcom,qsync-mode-min-refresh-rate = <1>;
		};

		timing_122_455: timing@122 {
			qcom,mdss-dsi-panel-phy-timings = [00 10 04 04 12 1e 04
				04 03 02 04 0e 09 00];
			qcom,display-topology = <2 0 1>;
			qcom,default-topology-index = <0>;
			qcom,qsync-mode-min-refresh-rate = <1>;
		};

		timing_123_456: timing@123 {
			qcom,mdss-dsi-panel-phy-timings = [00 0c 03 03 10 1d 03
				03 02 02 04 0b 08 00];
			qcom,display-topology = <2 0 1>;
			qcom,default-topology-index = <0>;
			qcom,qsync-mode-min-refresh-rate = <1>;
		};

		timing_124_457: timing@124 {
			qcom,mdss-dsi-panel-phy-timings = [00 0a 01 01 0e 1b 02
				01 01 02 04 09 06 00];
			qcom,display-topology = <2 0 1>;
			qcom,default-topology-index = <0>;
			qcom,qsync-mode-min-refresh-rate = <1>;
		};

		timing_125_458: timing@125 {
			qcom,mdss-dsi-panel-phy-timings = [00 22 09 09 19 23 09
				09 09 02 04 1d 0e 00];
			qcom,display-topology = <2 0 1>;
			qcom,default-topology-index = <0>;
			qcom,qsync-mode-min-refresh-rate = <1>;
		};

		timing_126_459: timing@126 {
			qcom,mdss-dsi-panel-phy-timings = [00 1c 07 07 17 22 07
				07 08 02 04 18 0c 00];
			qcom,display-topology = <2 0 1>;
			qcom,default-topology-index = <0>;
			qcom,qsync-mode-min-refresh-rate = <1>;
		};

		timing_127_460: timing@127 {
			qcom,mdss-dsi-panel-phy-timings = [00 17 05 05 14 1f 06
				06 06 02 04 14 0b 00];
			qcom,display-topology = <2 0 1>;
			qcom,default-topology-index = <0>;
			qcom,qsync-mode-min-refresh-rate = <1>;
		};

		timing_128_461: timing@128 {
			qcom,mdss-dsi-panel-phy-timings = [00 11 03 04 12 1e 04
				04 03 02 04 0e 09 00];
			qcom,display-topology = <2 0 1>;
			qcom,default-topology-index = <0>;
			qcom,qsync-mode-min-refresh-rate = <1>;
		};

		timing_129_462: timing@129 {
			qcom,mdss-dsi-panel-phy-timings = [00 30 0c 0d 1e 27 0c
				0d 0c 02 04 27 11 00];
			qcom,display-topology = <2 0 1>;
			qcom,default-topology-index = <0>;
			qcom,qsync-mode-min-refresh-rate = <1>;
		};

		timing_130_463: timing@130 {
			qcom,mdss-dsi-panel-phy-timings = [00 22 08 09 19 23 09
				09 09 02 04 1c 0e 00];
			qcom,display-topology = <2 0 1>;
			qcom,default-topology-index = <0>;
			qcom,qsync-mode-min-refresh-rate = <1>;
		};

		timing_131_464: timing@131 {
			qcom,mdss-dsi-panel-phy-timings = [00 3a 0f 0e 18 15 0e
				0f 0d 02 04 2d 12 00];
			qcom,display-topology = <2 0 1>;
			qcom,default-topology-index = <0>;
			qcom,qsync-mode-min-refresh-rate = <1>;
		};

		timing_132_465: timing@132 {
			qcom,mdss-dsi-panel-phy-timings = [00 2e 0c 0c 1d 27 0c
				0d 0b 02 04 25 11 00];
			qcom,display-topology = <2 0 1>;
			qcom,default-topology-index = <0>;
			qcom,qsync-mode-min-refresh-rate = <1>;
		};

		timing_133_466: timing@133 {
			qcom,mdss-dsi-panel-phy-timings = [00 24 0a 0a 1a 24 0a
				0a 09 02 04 1e 0f 00];
			qcom,display-topology = <2 0 1>;
			qcom,default-topology-index = <0>;
			qcom,qsync-mode-min-refresh-rate = <1>;
		};

		timing_134_467: timing@134 {
			qcom,mdss-dsi-panel-phy-timings = [00 21 08 08 19 23 08
				08 09 02 04 1c 0d 00];
			qcom,display-topology = <2 0 1>;
			qcom,default-topology-index = <0>;
			qcom,qsync-mode-min-refresh-rate = <1>;
		};

		timing_135_468: timing@135 {
			qcom,mdss-dsi-panel-phy-timings = [00 25 0a 0a 1b 24 0a
				0a 0a 02 04 1f 0f 00];
			qcom,display-topology = <2 0 1>;
			qcom,default-topology-index = <0>;
			qcom,qsync-mode-min-refresh-rate = <1>;
		};

		timing_136_469: timing@136 {
			qcom,mdss-dsi-panel-phy-timings = [00 24 09 0a 1a 25 09
				0a 09 02 04 1e 0f 00];
			qcom,display-topology = <2 0 1>;
			qcom,default-topology-index = <0>;
			qcom,qsync-mode-min-refresh-rate = <1>;
		};

		timing_137_470: timing@137 {
			qcom,mdss-dsi-panel-phy-timings = [00 22 09 09 19 23 09
				09 09 02 04 1d 0e 00];
			qcom,display-topology = <2 0 1>;
			qcom,default-topology-index = <0>;
			qcom,qsync-mode-min-refresh-rate = <1>;
		};

		timing_138_471: timing@138 {
			qcom,mdss-dsi-panel-phy-timings = [00 15 05 05 14 1f 05
				05 06 02 04 13 0a 00];
			qcom,display-topology = <2 0 1>;
			qcom,default-topology-index = <0>;
			qcom,qsync-mode-min-refresh-rate = <1>;
		};

		timing_139_472: timing@139 {
			qcom,mdss-dsi-panel-phy-timings = [00 13 05 04 13 1e 05
				05 06 02 04 12 0a 00];
			qcom,display-topology = <2 0 1>;
			qcom,default-topology-index = <0>;
			qcom,qsync-mode-min-refresh-rate = <1>;
		};

		timing_140_473: timing@140 {
			qcom,mdss-dsi-panel-phy-timings = [00 0a 02 02 0f 1c 02
				02 02 02 04 0a 07 00];
			qcom,display-topology = <2 0 1>;
			qcom,default-topology-index = <0>;
			qcom,qsync-mode-min-refresh-rate = <1>;
		};

		timing_141_474: timing@141 {
			qcom,mdss-dsi-panel-phy-timings = [00 54 16 16 23 1f 15
				17 13 02 04 40 1a 00];
			qcom,display-topology = <2 0 1>;
			qcom,default-topology-index = <0>;
			qcom,qsync-mode-min-refresh-rate = <1>;
		};

		timing_142_475: timing@142 {
			qcom,mdss-dsi-panel-phy-timings = [00 30 0d 0d 1e 28 0c
				0d 0c 02 04 27 12 00];
			qcom,display-topology = <2 0 1>;
			qcom,default-topology-index = <0>;
			qcom,qsync-mode-min-refresh-rate = <1>;
		};

		timing_143_476: timing@143 {
			qcom,mdss-dsi-panel-phy-timings = [00 2a 0a 0b 1b 26 0b
				0b 0a 02 04 22 10 00];
			qcom,display-topology = <2 0 1>;
			qcom,default-topology-index = <0>;
			qcom,qsync-mode-min-refresh-rate = <1>;
		};

		timing_144_477: timing@144 {
			qcom,mdss-dsi-panel-phy-timings = [00 2c 0b 0c 1c 27 0b
				0c 0b 02 04 24 10 00];
			qcom,display-topology = <2 0 1>;
			qcom,default-topology-index = <0>;
			qcom,qsync-mode-min-refresh-rate = <1>;
		};

		timing_145_478: timing@145 {
			qcom,mdss-dsi-panel-phy-timings = [00 3b 0f 0f 18 15 0f
				0f 0d 02 04 2d 12 00];
			qcom,display-topology = <2 0 1>;
			qcom,default-topology-index = <0>;
			qcom,qsync-mode-min-refresh-rate = <1>;
		};

		timing_146_479: timing@146 {
			qcom,mdss-dsi-panel-phy-timings = [00 23 09 09 1a 24 09
				09 09 02 04 1d 0e 00];
			qcom,display-topology = <2 0 1>;
			qcom,default-topology-index = <0>;
			qcom,qsync-mode-min-refresh-rate = <1>;
		};

		timing_147_480: timing@147 {
			qcom,mdss-dsi-panel-phy-timings = [00 22 09 09 19 23 09
				09 09 02 04 1d 0e 00];
			qcom,display-topology = <2 0 1>;
			qcom,default-topology-index = <0>;
			qcom,qsync-mode-min-refresh-rate = <1>;
		};

		timing_148_481: timing@148 {
			qcom,mdss-dsi-panel-phy-timings = [00 2b 0b 0b 1c 27 0b
				0c 0b 02 04 23 10 00];
			qcom,display-topology = <2 0 1>;
			qcom,default-topology-index = <0>;
			qcom,qsync-mode-min-refresh-rate = <1>;
		};

		timing_149_482: timing@149 {
			qcom,mdss-dsi-panel-phy-timings = [00 1a 07 06 16 21 07
				07 07 02 04 17 0c 00];
			qcom,display-topology = <2 0 1>;
			qcom,default-topology-index = <0>;
			qcom,qsync-mode-min-refresh-rate = <1>;
		};

		timing_150_483: timing@150 {
			qcom,mdss-dsi-panel-phy-timings = [00 19 06 06 15 1f 07
				06 07 02 04 16 0b 00];
			qcom,display-topology = <2 0 1>;
			qcom,default-topology-index = <0>;
			qcom,qsync-mode-min-refresh-rate = <1>;
		};

		timing_151_484: timing@151 {
			qcom,mdss-dsi-panel-phy-timings = [00 17 05 05 14 1f 06
				06 06 02 04 14 0b 00];
			qcom,display-topology = <2 0 1>;
			qcom,default-topology-index = <0>;
			qcom,qsync-mode-min-refresh-rate = <1>;
		};

		timing_152_485: timing@152 {
			qcom,mdss-dsi-panel-phy-timings = [00 1d 08 07 17 22 08
				08 08 02 04 19 0d 00];
			qcom,display-topology = <2 0 1>;
			qcom,default-topology-index = <0>;
			qcom,qsync-mode-min-refresh-rate = <1>;
		};

		timing_153_486: timing@153 {
			qcom,mdss-dsi-panel-phy-timings = [00 11 04 04 12 1e 04
				04 03 02 04 0f 09 00];
			qcom,display-topology = <2 0 1>;
			qcom,default-topology-index = <0>;
			qcom,qsync-mode-min-refresh-rate = <1>;
		};

		timing_154_487: timing@154 {
			qcom,mdss-dsi-panel-phy-timings = [00 0c 03 03 10 1d 03
				03 02 02 04 0b 08 00];
			qcom,display-topology = <2 0 1>;
			qcom,default-topology-index = <0>;
			qcom,qsync-mode-min-refresh-rate = <1>;
		};

		timing_155_488: timing@155 {
			qcom,mdss-dsi-panel-phy-timings = [00 2a 0b 0b 1c 26 0b
				0c 0b 02 04 23 10 00];
			qcom,display-topology = <2 0 1>;
			qcom,default-topology-index = <0>;
			qcom,qsync-mode-min-refresh-rate = <1>;
		};

		timing_156_489: timing@156 {
			qcom,mdss-dsi-panel-phy-timings = [00 21 08 08 19 22 09
				08 09 02 04 1c 0d 00];
			qcom,display-topology = <2 0 1>;
			qcom,default-topology-index = <0>;
			qcom,qsync-mode-min-refresh-rate = <1>;
		};

		timing_157_490: timing@157 {
			qcom,mdss-dsi-panel-phy-timings = [00 1b 07 06 16 21 07
				07 07 02 04 17 0c 00];
			qcom,display-topology = <2 0 1>;
			qcom,default-topology-index = <0>;
			qcom,qsync-mode-min-refresh-rate = <1>;
		};

		timing_158_491: timing@158 {
			qcom,mdss-dsi-panel-phy-timings = [00 4f 14 15 21 1c 14
				15 12 02 04 3c 18 00];
			qcom,display-topology = <2 0 1>;
			qcom,default-topology-index = <0>;
			qcom,qsync-mode-min-refresh-rate = <1>;
		};

		timing_159_492: timing@159 {
			qcom,mdss-dsi-panel-phy-timings = [00 4e 14 15 21 1b 14
				15 12 02 04 3c 18 00];
			qcom,display-topology = <2 0 1>;
			qcom,default-topology-index = <0>;
			qcom,qsync-mode-min-refresh-rate = <1>;
		};

		timing_160_493: timing@160 {
			qcom,mdss-dsi-panel-phy-timings = [00 2b 0b 0b 1c 27 0b
				0c 0b 02 04 23 10 00];
			qcom,display-topology = <2 0 1>;
			qcom,default-topology-index = <0>;
			qcom,qsync-mode-min-refresh-rate = <1>;
		};

		timing_161_494: timing@161 {
			qcom,mdss-dsi-panel-phy-timings = [00 27 0a 0a 1b 25 0a
				0b 0a 02 04 20 0f 00];
			qcom,display-topology = <2 0 1>;
			qcom,default-topology-index = <0>;
			qcom,qsync-mode-min-refresh-rate = <1>;
		};

		timing_162_495: timing@162 {
			qcom,mdss-dsi-panel-phy-timings = [00 20 08 08 18 23 08
				08 08 02 04 1b 0d 00];
			qcom,display-topology = <2 0 1>;
			qcom,default-topology-index = <0>;
			qcom,qsync-mode-min-refresh-rate = <1>;
		};

		timing_163_496: timing@163 {
			qcom,mdss-dsi-panel-phy-timings = [00 1a 07 06 16 21 07
				07 07 02 04 17 0c 00];
			qcom,display-topology = <2 0 1>;
			qcom,default-topology-index = <0>;
			qcom,qsync-mode-min-refresh-rate = <1>;
		};

		timing_164_497: timing@164 {
			qcom,mdss-dsi-panel-phy-timings = [00 38 0e 0e 17 13 0e
				0e 0d 02 04 2b 12 00];
			qcom,display-topology = <2 0 1>;
			qcom,default-topology-index = <0>;
			qcom,qsync-mode-min-refresh-rate = <1>;
		};

		timing_165_498: timing@165 {
			qcom,mdss-dsi-panel-phy-timings = [00 37 0e 0e 17 14 0d
				0e 0d 02 04 2b 11 00];
			qcom,display-topology = <2 0 1>;
			qcom,default-topology-index = <0>;
			qcom,qsync-mode-min-refresh-rate = <1>;
		};

		timing_166_499: timing@166 {
			qcom,mdss-dsi-panel-phy-timings = [00 24 09 09 1a 24 09
				09 09 02 04 1e 0e 00];
			qcom,display-topology = <2 0 1>;
			qcom,default-topology-index = <0>;
			qcom,qsync-mode-min-refresh-rate = <1>;
		};

		timing_167_500: timing@167 {
			qcom,mdss-dsi-panel-phy-timings = [00 1e 08 07 18 22 08
				08 08 02 04 1a 0d 00];
			qcom,display-topology = <2 0 1>;
			qcom,default-topology-index = <0>;
			qcom,qsync-mode-min-refresh-rate = <1>;
		};

		timing_168_501: timing@168 {
			qcom,mdss-dsi-panel-phy-timings = [00 29 0a 0b 1b 26 0a
				0b 0a 02 04 21 10 00];
			qcom,display-topology = <2 0 1>;
			qcom,default-topology-index = <0>;
			qcom,qsync-mode-min-refresh-rate = <1>;
		};

		timing_169_502: timing@169 {
			qcom,mdss-dsi-panel-phy-timings = [00 28 0a 0b 1b 26 0a
				0b 0a 02 04 21 0f 00];
			qcom,display-topology = <2 0 1>;
			qcom,default-topology-index = <0>;
			qcom,qsync-mode-min-refresh-rate = <1>;
		};

		timing_170_503: timing@170 {
			qcom,mdss-dsi-panel-phy-timings = [00 1f 08 07 18 22 08
				08 08 02 04 1a 0d 00];
			qcom,display-topology = <2 0 1>;
			qcom,default-topology-index = <0>;
			qcom,qsync-mode-min-refresh-rate = <1>;
		};

		timing_171_504: timing@171 {
			qcom,mdss-dsi-panel-phy-timings = [00 1d 07 07 17 22 07
				07 08 02 04 19 0c 00];
			qcom,display-topology = <2 0 1>;
			qcom,default-topology-index = <0>;
			qcom,qsync-mode-min-refresh-rate = <1>;
		};

		timing_172_505: timing@172 {
			qcom,mdss-dsi-panel-phy-timings = [00 1b 07 06 16 21 07
				07 07 02 04 17 0c 00];
			qcom,display-topology = <2 0 1>;
			qcom,default-topology-index = <0>;
			qcom,qsync-mode-min-refresh-rate = <1>;
		};

		timing_173_506: timing@173 {
			qcom,mdss-dsi-panel-phy-timings = [00 1f 08 07 18 22 08
				08 08 02 04 1a 0d 00];
			qcom,display-topology = <2 0 1>;
			qcom,default-topology-index = <0>;
			qcom,qsync-mode-min-refresh-rate = <1>;
		};

		timing_174_507: timing@174 {
			qcom,mdss-dsi-panel-phy-timings = [00 0b 02 02 0f 1c 03
				02 02 02 04 0a 07 00];
			qcom,display-topology = <2 0 1>;
			qcom,default-topology-index = <0>;
			qcom,qsync-mode-min-refresh-rate = <1>;
		};

		timing_175_508: timing@175 {
			qcom,mdss-dsi-panel-phy-timings = [00 0d 03 03 10 1d 04
				03 02 02 04 0c 08 00];
			qcom,display-topology = <2 0 1>;
			qcom,default-topology-index = <0>;
			qcom,qsync-mode-min-refresh-rate = <1>;
		};

		timing_176_509: timing@176 {
			qcom,mdss-dsi-panel-phy-timings = [00 0b 03 02 10 1d 03
				03 02 02 04 0b 08 00];
			qcom,display-topology = <2 0 1>;
			qcom,default-topology-index = <0>;
			qcom,qsync-mode-min-refresh-rate = <1>;
		};

		timing_177_510: timing@177 {
			qcom,mdss-dsi-panel-phy-timings = [00 1f 08 07 18 22 08
				08 08 02 04 1a 0d 00];
			qcom,display-topology = <2 0 1>;
			qcom,default-topology-index = <0>;
			qcom,qsync-mode-min-refresh-rate = <1>;
		};

		timing_178_511: timing@178 {
			qcom,mdss-dsi-panel-phy-timings = [00 1a 07 06 16 21 07
				07 07 02 04 17 0c 00];
			qcom,display-topology = <2 0 1>;
			qcom,default-topology-index = <0>;
			qcom,qsync-mode-min-refresh-rate = <1>;
		};

		timing_179_512: timing@179 {
			qcom,mdss-dsi-panel-phy-timings = [00 1c 07 07 17 21 07
				07 08 02 04 18 0c 00];
			qcom,display-topology = <2 0 1>;
			qcom,default-topology-index = <0>;
			qcom,qsync-mode-min-refresh-rate = <1>;
		};

		timing_180_513: timing@180 {
			qcom,mdss-dsi-panel-phy-timings = [00 17 06 05 15 1f 06
				06 07 02 04 15 0b 00];
			qcom,display-topology = <2 0 1>;
			qcom,default-topology-index = <0>;
			qcom,qsync-mode-min-refresh-rate = <1>;
		};

		timing_181_514: timing@181 {
			qcom,mdss-dsi-panel-phy-timings = [00 1e 08 07 18 22 08
				08 08 02 04 1a 0d 00];
			qcom,display-topology = <2 0 1>;
			qcom,default-topology-index = <0>;
			qcom,qsync-mode-min-refresh-rate = <1>;
		};

		timing_182_515: timing@182 {
			qcom,mdss-dsi-panel-phy-timings = [00 17 06 05 15 20 06
				06 07 02 04 15 0b 00];
			qcom,display-topology = <2 0 1>;
			qcom,default-topology-index = <0>;
			qcom,qsync-mode-min-refresh-rate = <1>;
		};

		timing_183_516: timing@183 {
			qcom,mdss-dsi-panel-phy-timings = [00 14 05 05 13 1f 05
				05 06 02 04 12 0a 00];
			qcom,display-topology = <2 0 1>;
			qcom,default-topology-index = <0>;
			qcom,qsync-mode-min-refresh-rate = <1>;
		};

		timing_184_517: timing@184 {
			qcom,mdss-dsi-panel-phy-timings = [00 11 04 04 12 1e 04
				04 03 02 04 0f 09 00];
			qcom,display-topology = <2 0 1>;
			qcom,default-topology-index = <0>;
			qcom,qsync-mode-min-refresh-rate = <1>;
		};

		timing_185_518: timing@185 {
			qcom,mdss-dsi-panel-phy-timings = [00 0f 03 03 11 1d 04
				04 03 02 04 0d 09 00];
			qcom,display-topology = <2 0 1>;
			qcom,default-topology-index = <0>;
			qcom,qsync-mode-min-refresh-rate = <1>;
		};

		timing_186_519: timing@186 {
			qcom,mdss-dsi-panel-phy-timings = [00 1f 08 07 18 22 08
				08 08 02 04 1a 0d 00];
			qcom,display-topology = <2 0 1>;
			qcom,default-topology-index = <0>;
			qcom,qsync-mode-min-refresh-rate = <1>;
		};

		timing_187_520: timing@187 {
			qcom,mdss-dsi-panel-phy-timings = [00 10 03 03 11 1e 04
				04 03 02 04 0e 09 00];
			qcom,display-topology = <2 0 1>;
			qcom,default-topology-index = <0>;
			qcom,qsync-mode-min-refresh-rate = <1>;
		};

		timing_188_521: timing@188 {
			qcom,mdss-dsi-panel-phy-timings = [00 0f 03 03 11 1d 04
				04 03 02 04 0d 09 00];
			qcom,display-topology = <2 0 1>;
			qcom,default-topology-index = <0>;
			qcom,qsync-mode-min-refresh-rate = <1>;
		};

		timing_189_522: timing@189 {
			qcom,mdss-dsi-panel-phy-timings = [00 0d 03 03 10 1c 04
				03 02 02 04 0c 08 00];
			qcom,display-topology = <2 0 1>;
			qcom,default-topology-index = <0>;
			qcom,qsync-mode-min-refresh-rate = <1>;
		};

		timing_190_523: timing@190 {
			qcom,mdss-dsi-panel-phy-timings = [00 16 05 05 14 1f 06
				06 06 02 04 13 0b 00];
			qcom,display-topology = <2 0 1>;
			qcom,default-topology-index = <0>;
			qcom,qsync-mode-min-refresh-rate = <1>;
		};

		timing_191_524: timing@191 {
			qcom,mdss-dsi-panel-phy-timings = [00 12 04 04 12 1e 04
				04 03 02 04 0f 09 00];
			qcom,display-topology = <2 0 1>;
			qcom,default-topology-index = <0>;
			qcom,qsync-mode-min-refresh-rate = <1>;
		};

		timing_192_525: timing@192 {
			qcom,mdss-dsi-panel-phy-timings = [00 0d 03 03 10 1d 03
				03 02 02 04 0c 08 00];
			qcom,display-topology = <2 0 1>;
			qcom,default-topology-index = <0>;
			qcom,qsync-mode-min-refresh-rate = <1>;
		};

		timing_193_526: timing@193 {
			qcom,mdss-dsi-panel-phy-timings = [03 08 00 01 0d 1b 01
				01 01 02 04 07 06 00];
			qcom,display-topology = <2 0 1>;
			qcom,default-topology-index = <0>;
			qcom,qsync-mode-min-refresh-rate = <1>;
		};

		timing_194_527: timing@194 {
			qcom,mdss-dsi-panel-phy-timings = [01 08 01 01 0e 1b 01
				01 02 02 04 08 06 00];
			qcom,display-topology = <2 0 1>;
			qcom,default-topology-index = <0>;
			qcom,qsync-mode-min-refresh-rate = <1>;
		};

		timing_195_528: timing@195 {
			qcom,mdss-dsi-panel-phy-timings = [00 2d 0c 0c 1d 27 0c
				0c 0b 02 04 25 11 00];
			qcom,display-topology = <2 0 1>;
			qcom,default-topology-index = <0>;
			qcom,qsync-mode-min-refresh-rate = <1>;
		};

		timing_196_529: timing@196 {
			qcom,mdss-dsi-panel-phy-timings = [00 21 08 08 19 23 08
				08 09 02 04 1c 0d 00];
			qcom,display-topology = <2 0 1>;
			qcom,default-topology-index = <0>;
			qcom,qsync-mode-min-refresh-rate = <1>;
		};

		timing_197_530: timing@197 {
			qcom,mdss-dsi-panel-phy-timings = [00 1a 07 06 16 21 07
				07 07 02 04 17 0c 00];
			qcom,display-topology = <2 0 1>;
			qcom,default-topology-index = <0>;
			qcom,qsync-mode-min-refresh-rate = <1>;
		};

		timing_198_531: timing@198 {
			qcom,mdss-dsi-panel-phy-timings = [00 11 03 04 12 1e 04
				04 03 02 04 0e 09 00];
			qcom,display-topology = <2 0 1>;
			qcom,default-topology-index = <0>;
			qcom,qsync-mode-min-refresh-rate = <1>;
		};

		timing_199_532: timing@199 {
			qcom,mdss-dsi-panel-phy-timings = [00 1b 06 06 16 20 07
				07 07 02 04 17 0c 00];
			qcom,display-topology = <2 0 1>;
			qcom,default-topology-index = <0>;
			qcom,qsync-mode-min-refresh-rate = <1>;
		};

		timing_200_533: timing@200 {
			qcom,mdss-dsi-panel-phy-timings = [00 15 05 05 14 1f 05
				05 06 02 04 13 0a 00];
			qcom,display-topology = <2 0 1>;
			qcom,default-topology-index = <0>;
			qcom,qsync-mode-min-refresh-rate = <1>;
		};

		timing_201_534: timing@201 {
			qcom,mdss-dsi-panel-phy-timings = [00 11 03 04 12 1e 04
				04 03 02 04 0e 09 00];
			qcom,display-topology = <2 0 1>;
			qcom,default-topology-index = <0>;
			qcom,qsync-mode-min-refresh-rate = <1>;
		};

		timing_202_535: timing@202 {
			qcom,mdss-dsi-panel-phy-timings = [00 29 0b 0b 1b 26 0b
				0b 0a 02 04 22 10 00];
			qcom,display-topology = <2 0 1>;
			qcom,default-topology-index = <0>;
			qcom,qsync-mode-min-refresh-rate = <1>;
		};

		timing_203_536: timing@203 {
			qcom,mdss-dsi-panel-phy-timings = [00 28 0a 0b 1b 26 0a
				0b 0a 02 04 21 0f 00];
			qcom,display-topology = <2 0 1>;
			qcom,default-topology-index = <0>;
			qcom,qsync-mode-min-refresh-rate = <1>;
		};

		timing_204_537: timing@204 {
			qcom,mdss-dsi-panel-phy-timings = [00 24 09 09 1a 24 09
				09 09 02 04 1e 0e 00];
			qcom,display-topology = <2 0 1>;
			qcom,default-topology-index = <0>;
			qcom,qsync-mode-min-refresh-rate = <1>;
		};

		timing_205_538: timing@205 {
			qcom,mdss-dsi-panel-phy-timings = [00 23 09 09 1a 24 09
				09 09 02 04 1d 0e 00];
			qcom,display-topology = <2 0 1>;
			qcom,default-topology-index = <0>;
			qcom,qsync-mode-min-refresh-rate = <1>;
		};

		timing_206_539: timing@206 {
			qcom,mdss-dsi-panel-phy-timings = [00 1e 08 07 18 22 08
				08 08 02 04 1a 0d 00];
			qcom,display-topology = <2 0 1>;
			qcom,default-topology-index = <0>;
			qcom,qsync-mode-min-refresh-rate = <1>;
		};

		timing_207_540: timing@207 {
			qcom,mdss-dsi-panel-phy-timings = [00 0a 01 02 0f 1c 02
				02 02 02 04 09 07 00];
			qcom,display-topology = <2 0 1>;
			qcom,default-topology-index = <0>;
			qcom,qsync-mode-min-refresh-rate = <1>;
		};

		timing_208_541: timing@208 {
			qcom,mdss-dsi-panel-phy-timings = [00 22 08 09 19 23 09
				09 09 02 04 1c 0e 00];
			qcom,display-topology = <2 0 1>;
			qcom,default-topology-index = <0>;
			qcom,qsync-mode-min-refresh-rate = <1>;
		};

		timing_209_542: timing@209 {
			qcom,mdss-dsi-panel-phy-timings = [00 17 05 05 14 1f 06
				06 06 02 04 14 0b 00];
			qcom,display-topology = <2 0 1>;
			qcom,default-topology-index = <0>;
			qcom,qsync-mode-min-refresh-rate = <1>;
		};

		timing_210_543: timing@210 {
			qcom,mdss-dsi-panel-phy-timings = [00 22 08 08 19 23 09
				08 09 02 04 1c 0d 00];
			qcom,display-topology = <2 0 1>;
			qcom,default-topology-index = <0>;
			qcom,qsync-mode-min-refresh-rate = <1>;
		};

		timing_211_544: timing@211 {
			qcom,mdss-dsi-panel-phy-timings = [00 21 08 08 19 22 09
				08 09 02 04 1c 0d 00];
			qcom,display-topology = <2 0 1>;
			qcom,default-topology-index = <0>;
			qcom,qsync-mode-min-refresh-rate = <1>;
		};

		timing_212_545: timing@212 {
			qcom,mdss-dsi-panel-phy-timings = [00 14 05 05 13 1f 05
				05 06 02 04 12 0a 00];
			qcom,display-topology = <2 0 1>;
			qcom,default-topology-index = <0>;
			qcom,qsync-mode-min-refresh-rate = <1>;
		};

		timing_213_546: timing@213 {
			qcom,mdss-dsi-panel-phy-timings = [00 19 06 06 15 1f 07
				06 07 02 04 16 0b 00];
			qcom,display-topology = <2 0 1>;
			qcom,default-topology-index = <0>;
			qcom,qsync-mode-min-refresh-rate = <1>;
		};

		timing_214_547: timing@214 {
			qcom,mdss-dsi-panel-phy-timings = [00 22 08 08 19 23 09
				08 09 02 04 1c 0d 00];
			qcom,display-topology = <2 0 1>;
			qcom,default-topology-index = <0>;
			qcom,qsync-mode-min-refresh-rate = <1>;
		};

		timing_215_548: timing@215 {
			qcom,mdss-dsi-panel-phy-timings = [00 16 05 05 14 1f 06
				06 06 02 04 13 0b 00];
			qcom,display-topology = <2 0 1>;
			qcom,default-topology-index = <0>;
			qcom,qsync-mode-min-refresh-rate = <1>;
		};

		timing_216_549: timing@216 {
			qcom,mdss-dsi-panel-phy-timings = [00 21 08 08 19 23 09
				08 09 02 04 1c 0d 00];
			qcom,display-topology = <2 0 1>;
			qcom,default-topology-index = <0>;
			qcom,qsync-mode-min-refresh-rate = <1>;
		};

		timing_217_550: timing@217 {
			qcom,mdss-dsi-panel-phy-timings = [00 1a 06 06 16 20 07
				06 07 02 04 16 0b 00];
			qcom,display-topology = <2 0 1>;
			qcom,default-topology-index = <0>;
			qcom,qsync-mode-min-refresh-rate = <1>;
		};

		timing_218_551: timing@218 {
			qcom,mdss-dsi-panel-phy-timings = [00 20 08 08 18 23 08
				08 08 02 04 1b 0d 00];
			qcom,display-topology = <2 0 1>;
			qcom,default-topology-index = <0>;
			qcom,qsync-mode-min-refresh-rate = <1>;
		};

		timing_219_552: timing@219 {
			qcom,mdss-dsi-panel-phy-timings = [00 23 09 09 1a 24 09
				09 09 02 04 1d 0e 00];
			qcom,display-topology = <2 0 1>;
			qcom,default-topology-index = <0>;
			qcom,qsync-mode-min-refresh-rate = <1>;
		};

		timing_220_553: timing@220 {
			qcom,mdss-dsi-panel-phy-timings = [00 18 06 06 15 20 06
				06 07 02 04 15 0b 00];
			qcom,display-topology = <2 0 1>;
			qcom,default-topology-index = <0>;
			qcom,qsync-mode-min-refresh-rate = <1>;
		};

		timing_221_554: timing@221 {
			qcom,mdss-dsi-panel-phy-timings = [00 13 04 04 13 1e 05
				05 04 02 04 10 0a 00];
			qcom,display-topology = <2 0 1>;
			qcom,default-topology-index = <0>;
			qcom,qsync-mode-min-refresh-rate = <1>;
		};

		timing_222_555: timing@222 {
			qcom,mdss-dsi-panel-phy-timings = [00 18 06 06 15 20 06
				06 07 02 04 15 0b 00];
			qcom,display-topology = <2 0 1>;
			qcom,default-topology-index = <0>;
			qcom,qsync-mode-min-refresh-rate = <1>;
		};

		timing_223_556: timing@223 {
			qcom,mdss-dsi-panel-phy-timings = [00 16 06 05 14 1f 06
				06 06 02 04 14 0b 00];
			qcom,display-topology = <2 0 1>;
			qcom,default-topology-index = <0>;
			qcom,qsync-mode-min-refresh-rate = <1>;
		};

		timing_224_557: timing@224 {
			qcom,mdss-dsi-panel-phy-timings = [00 13 05 04 13 1e 05
				05 06 02 04 12 0a 00];
			qcom,display-topology = <2 0 1>;
			qcom,default-topology-index = <0>;
			qcom,qsync-mode-min-refresh-rate = <1>;
		};

		timing_225_558: timing@225 {
			qcom,mdss-dsi-panel-phy-timings = [00 0c 03 03 10 1d 03
				03 02 02 04 0b 08 00];
			qcom,display-topology = <2 0 1>;
			qcom,default-topology-index = <0>;
			qcom,qsync-mode-min-refresh-rate = <1>;
		};

		timing_226_559: timing@226 {
			qcom,mdss-dsi-panel-phy-timings = [00 0e 03 03 11 1d 04
				04 03 02 04 0d 09 00];
			qcom,display-topology = <2 0 1>;
			qcom,default-topology-index = <0>;
			qcom,qsync-mode-min-refresh-rate = <1>;
		};

		timing_227_560: timing@227 {
			qcom,mdss-dsi-panel-phy-timings = [00 0d 03 03 10 1c 04
				03 02 02 04 0c 08 00];
			qcom,display-topology = <2 0 1>;
			qcom,default-topology-index = <0>;
			qcom,qsync-mode-min-refresh-rate = <1>;
		};

		timing_228_561: timing@228 {
			qcom,mdss-dsi-panel-phy-timings = [00 27 0a 0a 1b 25 0a
				0b 0a 02 04 20 0f 00];
			qcom,display-topology = <2 0 1>;
			qcom,default-topology-index = <0>;
			qcom,qsync-mode-min-refresh-rate = <1>;
		};

		timing_229_562: timing@229 {
			qcom,mdss-dsi-panel-phy-timings = [00 22 09 09 19 24 09
				09 09 02 04 1d 0e 00];
			qcom,display-topology = <2 0 1>;
			qcom,default-topology-index = <0>;
			qcom,qsync-mode-min-refresh-rate = <1>;
		};

		timing_230_563: timing@230 {
			qcom,mdss-dsi-panel-phy-timings = [00 1b 07 06 16 21 07
				07 07 02 04 17 0c 00];
			qcom,display-topology = <2 0 1>;
			qcom,default-topology-index = <0>;
			qcom,qsync-mode-min-refresh-rate = <1>;
		};

		timing_231_564: timing@231 {
			qcom,mdss-dsi-panel-phy-timings = [00 16 05 05 14 1e 06
				05 06 02 04 13 0a 00];
			qcom,display-topology = <2 0 1>;
			qcom,default-topology-index = <0>;
			qcom,qsync-mode-min-refresh-rate = <1>;
		};

		timing_232_565: timing@232 {
			qcom,mdss-dsi-panel-phy-timings = [00 10 03 03 11 1e 04
				04 03 02 04 0e 09 00];
			qcom,display-topology = <2 0 1>;
			qcom,default-topology-index = <0>;
			qcom,qsync-mode-min-refresh-rate = <1>;
		};

		timing_233_566: timing@233 {
			qcom,mdss-dsi-panel-phy-timings = [00 2f 0c 0c 1e 27 0c
				0d 0c 02 04 26 11 00];
			qcom,display-topology = <2 0 1>;
			qcom,default-topology-index = <0>;
			qcom,qsync-mode-min-refresh-rate = <1>;
		};

		timing_234_567: timing@234 {
			qcom,mdss-dsi-panel-phy-timings = [00 16 05 05 14 1f 06
				06 06 02 04 13 0b 00];
			qcom,display-topology = <2 0 1>;
			qcom,default-topology-index = <0>;
			qcom,qsync-mode-min-refresh-rate = <1>;
		};

		timing_235_568: timing@235 {
			qcom,mdss-dsi-panel-phy-timings = [00 13 05 04 13 1e 05
				05 06 02 04 12 0a 00];
			qcom,display-topology = <2 0 1>;
			qcom,default-topology-index = <0>;
			qcom,qsync-mode-min-refresh-rate = <1>;
		};

		timing_236_569: timing@236 {
			qcom,mdss-dsi-panel-phy-timings = [00 21 08 08 19 22 09
				08 09 02 04 1c 0d 00];
			qcom,display-topology = <2 0 1>;
			qcom,default-topology-index = <0>;
			qcom,qsync-mode-min-refresh-rate = <1>;
		};

		timing_237_570: timing@237 {
			qcom,mdss-dsi-panel-phy-timings = [00 11 03 04 12 1e 04
				04 03 02 04 0e 09 00];
			qcom,display-topology = <2 0 1>;
			qcom,default-topology-index = <0>;
			qcom,qsync-mode-min-refresh-rate = <1>;
		};

		timing_238_571: timing@238 {
			qcom,mdss-dsi-panel-phy-timings = [00 1a 06 06 16 20 07
				06 07 02 04 16 0b 00];
			qcom,display-topology = <2 0 1>;
			qcom,default-topology-index = <0>;
			qcom,qsync-mode-min-refresh-rate = <1>;
		};

		timing_239_572: timing@239 {
			qcom,mdss-dsi-panel-phy-timings = [01 09 01 01 0e 1b 01
				01 02 02 04 08 06 00];
			qcom,display-topology = <2 0 1>;
			qcom,default-topology-index = <0>;
			qcom,qsync-mode-min-refresh-rate = <1>;
		};

		timing_240_573: timing@240 {
			qcom,mdss-dsi-panel-phy-timings = [00 13 04 04 13 1f 04
				05 04 02 04 10 0a 00];
			qcom,display-topology = <2 0 1>;
			qcom,default-topology-index = <0>;
			qcom,qsync-mode-min-refresh-rate = <1>;
		};

		timing_241_574: timing@241 {
			qcom,mdss-dsi-panel-phy-timings = [00 0a 02 02 0f 1c 02
				02 02 02 04 0a 07 00];
			qcom,display-topology = <2 0 1>;
			qcom,default-topology-index = <0>;
			qcom,qsync-mode-min-refresh-rate = <1>;
		};

		timing_242_575: timing@242 {
			qcom,mdss-dsi-panel-phy-timings = [00 09 01 01 0e 1b 02
				01 01 02 04 08 06 00];
			qcom,display-topology = <2 0 1>;
			qcom,default-topology-index = <0>;
			qcom,qsync-mode-min-refresh-rate = <1>;
		};

		timing_243_576: timing@243 {
			qcom,mdss-dsi-panel-phy-timings = [00 0a 01 02 0f 1c 02
				02 02 02 04 09 07 00];
			qcom,display-topology = <2 0 1>;
			qcom,default-topology-index = <0>;
			qcom,qsync-mode-min-refresh-rate = <1>;
		};

		timing_244_577: timing@244 {
			qcom,mdss-dsi-panel-phy-timings = [00 2e 0c 0c 1d 27 0c
				0d 0b 02 04 25 11 00];
			qcom,display-topology = <2 0 1>;
			qcom,default-topology-index = <0>;
			qcom,qsync-mode-min-refresh-rate = <1>;
		};

		timing_245_578: timing@245 {
			qcom,mdss-dsi-panel-phy-timings = [00 20 08 08 18 23 08
				08 08 02 04 1b 0d 00];
			qcom,display-topology = <2 0 1>;
			qcom,default-topology-index = <0>;
			qcom,qsync-mode-min-refresh-rate = <1>;
		};

		timing_246_579: timing@246 {
			qcom,mdss-dsi-panel-phy-timings = [00 19 06 06 15 20 07
				06 07 02 04 16 0b 00];
			qcom,display-topology = <2 0 1>;
			qcom,default-topology-index = <0>;
			qcom,qsync-mode-min-refresh-rate = <1>;
		};

		timing_247_580: timing@247 {
			qcom,mdss-dsi-panel-phy-timings = [00 12 04 04 12 1e 04
				05 03 02 04 0f 0a 00];
			qcom,display-topology = <2 0 1>;
			qcom,default-topology-index = <0>;
			qcom,qsync-mode-min-refresh-rate = <1>;
		};

		timing_248_581: timing@248 {
			qcom,mdss-dsi-panel-phy-timings = [00 0a 01 02 0e 1c 02
				02 01 02 04 09 07 00];
			qcom,display-topology = <2 0 1>;
			qcom,default-topology-index = <0>;
			qcom,qsync-mode-min-refresh-rate = <1>;
		};

		timing_249_582: timing@249 {
			qcom,mdss-dsi-panel-phy-timings = [00 2d 0c 0c 1d 27 0c
				0d 0b 02 04 25 11 00];
			qcom,display-topology = <2 0 1>;
			qcom,default-topology-index = <0>;
			qcom,qsync-mode-min-refresh-rate = <1>;
		};

		timing_250_583: timing@250 {
			qcom,mdss-dsi-panel-phy-timings = [00 20 08 08 18 23 08
				08 08 02 04 1b 0d 00];
			qcom,display-topology = <2 0 1>;
			qcom,default-topology-index = <0>;
			qcom,qsync-mode-min-refresh-rate = <1>;
		};

		timing_251_584: timing@251 {
			qcom,mdss-dsi-panel-phy-timings = [00 19 06 06 15 20 07
				06 07 02 04 16 0b 00];
			qcom,display-topology = <2 0 1>;
			qcom,default-topology-index = <0>;
			qcom,qsync-mode-min-refresh-rate = <1>;
		};

		timing_252_585: timing@252 {
			qcom,mdss-dsi-panel-phy-timings = [00 13 04 04 13 1e 05
				05 04 02 04 10 0a 00];
			qcom,display-topology = <2 0 1>;
			qcom,default-topology-index = <0>;
			qcom,qsync-mode-min-refresh-rate = <1>;
		};

		timing_253_586: timing@253 {
			qcom,mdss-dsi-panel-phy-timings = [00 0a 02 02 0f 1c 02
				02 02 02 04 0a 07 00];
			qcom,display-topology = <2 0 1>;
			qcom,default-topology-index = <0>;
			qcom,qsync-mode-min-refresh-rate = <1>;
		};

		timing_254_587: timing@254 {
			qcom,mdss-dsi-panel-phy-timings = [00 0a 01 02 0e 1c 02
				02 01 02 04 09 07 00];
			qcom,display-topology = <2 0 1>;
			qcom,default-topology-index = <0>;
			qcom,qsync-mode-min-refresh-rate = <1>;
		};

		timing_255_588: timing@255 {
			qcom,mdss-dsi-panel-phy-timings = [03 08 00 01 0d 1b 01
				01 01 02 04 07 06 00];
			qcom,display-topology = <2 0 1>;
			qcom,default-topology-index = <0>;
			qcom,qsync-mode-min-refresh-rate = <1>;
		};
	};
};
